[part 1 of 12: package /AUTOSAR_Dem/SwComponentTypes]
AUTOSAR XML (schema 4-2-2)
package /AUTOSAR_Dem/SwComponentTypes
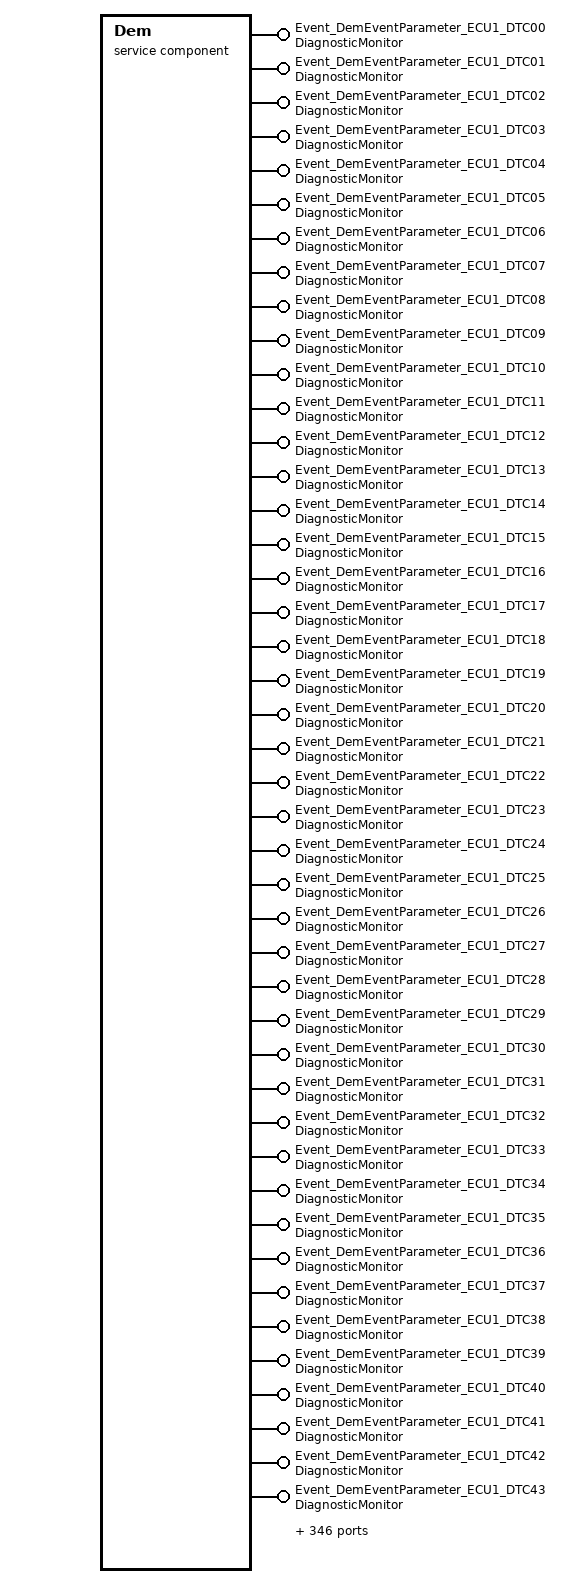
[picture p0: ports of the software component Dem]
  service sw component type Dem
    2013 x provide port:
      Event_DemEventParameter_ECU1_DTC00: provided-interface=DiagnosticMonitor
        provided-com-specs:
          operation=SetEventStatus, queue-length=1
          operation=SetEventStatusWithEnvdata, queue-length=1
          operation=ResetEventStatus, queue-length=1
          operation=PrestoreFreezeFrame, queue-length=1
          operation=ClearPrestoredFreezeFrame, queue-length=1
          operation=ResetEventDebounceStatus, queue-length=1
          operation=SetEventDisabled, queue-length=1
      Event_DemEventParameter_ECU1_DTC01: provided-interface=DiagnosticMonitor
        provided-com-specs:
          operation=SetEventStatus, queue-length=1
          operation=SetEventStatusWithEnvdata, queue-length=1
          operation=ResetEventStatus, queue-length=1
          operation=PrestoreFreezeFrame, queue-length=1
          operation=ClearPrestoredFreezeFrame, queue-length=1
          operation=ResetEventDebounceStatus, queue-length=1
          operation=SetEventDisabled, queue-length=1
      Event_DemEventParameter_ECU1_DTC02: provided-interface=DiagnosticMonitor
        provided-com-specs:
          operation=SetEventStatus, queue-length=1
          operation=SetEventStatusWithEnvdata, queue-length=1
          operation=ResetEventStatus, queue-length=1
          operation=PrestoreFreezeFrame, queue-length=1
          operation=ClearPrestoredFreezeFrame, queue-length=1
          operation=ResetEventDebounceStatus, queue-length=1
          operation=SetEventDisabled, queue-length=1
      Event_DemEventParameter_ECU1_DTC03: provided-interface=DiagnosticMonitor
        provided-com-specs:
          operation=SetEventStatus, queue-length=1
          operation=SetEventStatusWithEnvdata, queue-length=1
          operation=ResetEventStatus, queue-length=1
          operation=PrestoreFreezeFrame, queue-length=1
          operation=ClearPrestoredFreezeFrame, queue-length=1
          operation=ResetEventDebounceStatus, queue-length=1
          operation=SetEventDisabled, queue-length=1
      Event_DemEventParameter_ECU1_DTC04: provided-interface=DiagnosticMonitor
        provided-com-specs:
          operation=SetEventStatus, queue-length=1
          operation=SetEventStatusWithEnvdata, queue-length=1
          operation=ResetEventStatus, queue-length=1
          operation=PrestoreFreezeFrame, queue-length=1
          operation=ClearPrestoredFreezeFrame, queue-length=1
          operation=ResetEventDebounceStatus, queue-length=1
          operation=SetEventDisabled, queue-length=1
      Event_DemEventParameter_ECU1_DTC05: provided-interface=DiagnosticMonitor
        provided-com-specs:
          operation=SetEventStatus, queue-length=1
          operation=SetEventStatusWithEnvdata, queue-length=1
          operation=ResetEventStatus, queue-length=1
          operation=PrestoreFreezeFrame, queue-length=1
          operation=ClearPrestoredFreezeFrame, queue-length=1
          operation=ResetEventDebounceStatus, queue-length=1
          operation=SetEventDisabled, queue-length=1
      Event_DemEventParameter_ECU1_DTC06: provided-interface=DiagnosticMonitor
        provided-com-specs:
          operation=SetEventStatus, queue-length=1
          operation=SetEventStatusWithEnvdata, queue-length=1
          operation=ResetEventStatus, queue-length=1
          operation=PrestoreFreezeFrame, queue-length=1
          operation=ClearPrestoredFreezeFrame, queue-length=1
          operation=ResetEventDebounceStatus, queue-length=1
          operation=SetEventDisabled, queue-length=1
      Event_DemEventParameter_ECU1_DTC07: provided-interface=DiagnosticMonitor
        provided-com-specs:
          operation=SetEventStatus, queue-length=1
          operation=SetEventStatusWithEnvdata, queue-length=1
          operation=ResetEventStatus, queue-length=1
          operation=PrestoreFreezeFrame, queue-length=1
          operation=ClearPrestoredFreezeFrame, queue-length=1
          operation=ResetEventDebounceStatus, queue-length=1
          operation=SetEventDisabled, queue-length=1
      Event_DemEventParameter_ECU1_DTC08: provided-interface=DiagnosticMonitor
        provided-com-specs:
          operation=SetEventStatus, queue-length=1
          operation=SetEventStatusWithEnvdata, queue-length=1
          operation=ResetEventStatus, queue-length=1
          operation=PrestoreFreezeFrame, queue-length=1
          operation=ClearPrestoredFreezeFrame, queue-length=1
          operation=ResetEventDebounceStatus, queue-length=1
          operation=SetEventDisabled, queue-length=1
      Event_DemEventParameter_ECU1_DTC09: provided-interface=DiagnosticMonitor
        provided-com-specs:
          operation=SetEventStatus, queue-length=1
          operation=SetEventStatusWithEnvdata, queue-length=1
          operation=ResetEventStatus, queue-length=1
          operation=PrestoreFreezeFrame, queue-length=1
          operation=ClearPrestoredFreezeFrame, queue-length=1
          operation=ResetEventDebounceStatus, queue-length=1
          operation=SetEventDisabled, queue-length=1
      Event_DemEventParameter_ECU1_DTC10: provided-interface=DiagnosticMonitor
        provided-com-specs:
          operation=SetEventStatus, queue-length=1
          operation=SetEventStatusWithEnvdata, queue-length=1
          operation=ResetEventStatus, queue-length=1
          operation=PrestoreFreezeFrame, queue-length=1
          operation=ClearPrestoredFreezeFrame, queue-length=1
          operation=ResetEventDebounceStatus, queue-length=1
          operation=SetEventDisabled, queue-length=1
      Event_DemEventParameter_ECU1_DTC11: provided-interface=DiagnosticMonitor
        provided-com-specs:
          operation=SetEventStatus, queue-length=1
          operation=SetEventStatusWithEnvdata, queue-length=1
          operation=ResetEventStatus, queue-length=1
          operation=PrestoreFreezeFrame, queue-length=1
          operation=ClearPrestoredFreezeFrame, queue-length=1
          operation=ResetEventDebounceStatus, queue-length=1
          operation=SetEventDisabled, queue-length=1
      Event_DemEventParameter_ECU1_DTC12: provided-interface=DiagnosticMonitor
        provided-com-specs:
          operation=SetEventStatus, queue-length=1
          operation=SetEventStatusWithEnvdata, queue-length=1
          operation=ResetEventStatus, queue-length=1
          operation=PrestoreFreezeFrame, queue-length=1
          operation=ClearPrestoredFreezeFrame, queue-length=1
          operation=ResetEventDebounceStatus, queue-length=1
          operation=SetEventDisabled, queue-length=1
      Event_DemEventParameter_ECU1_DTC13: provided-interface=DiagnosticMonitor
        provided-com-specs:
          operation=SetEventStatus, queue-length=1
          operation=SetEventStatusWithEnvdata, queue-length=1
          operation=ResetEventStatus, queue-length=1
          operation=PrestoreFreezeFrame, queue-length=1
          operation=ClearPrestoredFreezeFrame, queue-length=1
          operation=ResetEventDebounceStatus, queue-length=1
          operation=SetEventDisabled, queue-length=1
      Event_DemEventParameter_ECU1_DTC14: provided-interface=DiagnosticMonitor
        provided-com-specs:
          operation=SetEventStatus, queue-length=1
          operation=SetEventStatusWithEnvdata, queue-length=1
          operation=ResetEventStatus, queue-length=1
          operation=PrestoreFreezeFrame, queue-length=1
          operation=ClearPrestoredFreezeFrame, queue-length=1
          operation=ResetEventDebounceStatus, queue-length=1
          operation=SetEventDisabled, queue-length=1
      Event_DemEventParameter_ECU1_DTC15: provided-interface=DiagnosticMonitor
        provided-com-specs:
          operation=SetEventStatus, queue-length=1
          operation=SetEventStatusWithEnvdata, queue-length=1
          operation=ResetEventStatus, queue-length=1
          operation=PrestoreFreezeFrame, queue-length=1
          operation=ClearPrestoredFreezeFrame, queue-length=1
          operation=ResetEventDebounceStatus, queue-length=1
          operation=SetEventDisabled, queue-length=1
      Event_DemEventParameter_ECU1_DTC16: provided-interface=DiagnosticMonitor
        provided-com-specs:
          operation=SetEventStatus, queue-length=1
          operation=SetEventStatusWithEnvdata, queue-length=1
          operation=ResetEventStatus, queue-length=1
          operation=PrestoreFreezeFrame, queue-length=1
          operation=ClearPrestoredFreezeFrame, queue-length=1
          operation=ResetEventDebounceStatus, queue-length=1
          operation=SetEventDisabled, queue-length=1
      Event_DemEventParameter_ECU1_DTC17: provided-interface=DiagnosticMonitor
        provided-com-specs:
          operation=SetEventStatus, queue-length=1
          operation=SetEventStatusWithEnvdata, queue-length=1
          operation=ResetEventStatus, queue-length=1
          operation=PrestoreFreezeFrame, queue-length=1
          operation=ClearPrestoredFreezeFrame, queue-length=1
          operation=ResetEventDebounceStatus, queue-length=1
          operation=SetEventDisabled, queue-length=1
      Event_DemEventParameter_ECU1_DTC18: provided-interface=DiagnosticMonitor
        provided-com-specs:
          operation=SetEventStatus, queue-length=1
          operation=SetEventStatusWithEnvdata, queue-length=1
          operation=ResetEventStatus, queue-length=1
          operation=PrestoreFreezeFrame, queue-length=1
          operation=ClearPrestoredFreezeFrame, queue-length=1
          operation=ResetEventDebounceStatus, queue-length=1
          operation=SetEventDisabled, queue-length=1
      Event_DemEventParameter_ECU1_DTC19: provided-interface=DiagnosticMonitor
        provided-com-specs:
          operation=SetEventStatus, queue-length=1
          operation=SetEventStatusWithEnvdata, queue-length=1
          operation=ResetEventStatus, queue-length=1
          operation=PrestoreFreezeFrame, queue-length=1
          operation=ClearPrestoredFreezeFrame, queue-length=1
          operation=ResetEventDebounceStatus, queue-length=1
          operation=SetEventDisabled, queue-length=1
      Event_DemEventParameter_ECU1_DTC20: provided-interface=DiagnosticMonitor
        provided-com-specs:
          operation=SetEventStatus, queue-length=1
          operation=SetEventStatusWithEnvdata, queue-length=1
          operation=ResetEventStatus, queue-length=1
          operation=PrestoreFreezeFrame, queue-length=1
          operation=ClearPrestoredFreezeFrame, queue-length=1
          operation=ResetEventDebounceStatus, queue-length=1
          operation=SetEventDisabled, queue-length=1
      Event_DemEventParameter_ECU1_DTC21: provided-interface=DiagnosticMonitor
        provided-com-specs:
          operation=SetEventStatus, queue-length=1
          operation=SetEventStatusWithEnvdata, queue-length=1
          operation=ResetEventStatus, queue-length=1
          operation=PrestoreFreezeFrame, queue-length=1
          operation=ClearPrestoredFreezeFrame, queue-length=1
          operation=ResetEventDebounceStatus, queue-length=1
          operation=SetEventDisabled, queue-length=1
      Event_DemEventParameter_ECU1_DTC22: provided-interface=DiagnosticMonitor
        provided-com-specs:
          operation=SetEventStatus, queue-length=1
          operation=SetEventStatusWithEnvdata, queue-length=1
          operation=ResetEventStatus, queue-length=1
          operation=PrestoreFreezeFrame, queue-length=1
          operation=ClearPrestoredFreezeFrame, queue-length=1
          operation=ResetEventDebounceStatus, queue-length=1
          operation=SetEventDisabled, queue-length=1
      Event_DemEventParameter_ECU1_DTC23: provided-interface=DiagnosticMonitor
        provided-com-specs:
          operation=SetEventStatus, queue-length=1
          operation=SetEventStatusWithEnvdata, queue-length=1
          operation=ResetEventStatus, queue-length=1
          operation=PrestoreFreezeFrame, queue-length=1
          operation=ClearPrestoredFreezeFrame, queue-length=1
          operation=ResetEventDebounceStatus, queue-length=1
          operation=SetEventDisabled, queue-length=1
      Event_DemEventParameter_ECU1_DTC24: provided-interface=DiagnosticMonitor
        provided-com-specs:
          operation=SetEventStatus, queue-length=1
          operation=SetEventStatusWithEnvdata, queue-length=1
          operation=ResetEventStatus, queue-length=1
          operation=PrestoreFreezeFrame, queue-length=1
          operation=ClearPrestoredFreezeFrame, queue-length=1
          operation=ResetEventDebounceStatus, queue-length=1
          operation=SetEventDisabled, queue-length=1
      Event_DemEventParameter_ECU1_DTC25: provided-interface=DiagnosticMonitor
        provided-com-specs:
          operation=SetEventStatus, queue-length=1
          operation=SetEventStatusWithEnvdata, queue-length=1
          operation=ResetEventStatus, queue-length=1
          operation=PrestoreFreezeFrame, queue-length=1
          operation=ClearPrestoredFreezeFrame, queue-length=1
          operation=ResetEventDebounceStatus, queue-length=1
          operation=SetEventDisabled, queue-length=1
      Event_DemEventParameter_ECU1_DTC26: provided-interface=DiagnosticMonitor
        provided-com-specs:
          operation=SetEventStatus, queue-length=1
          operation=SetEventStatusWithEnvdata, queue-length=1
          operation=ResetEventStatus, queue-length=1
          operation=PrestoreFreezeFrame, queue-length=1
          operation=ClearPrestoredFreezeFrame, queue-length=1
          operation=ResetEventDebounceStatus, queue-length=1
          operation=SetEventDisabled, queue-length=1
      Event_DemEventParameter_ECU1_DTC27: provided-interface=DiagnosticMonitor
        provided-com-specs:
          operation=SetEventStatus, queue-length=1
          operation=SetEventStatusWithEnvdata, queue-length=1
          operation=ResetEventStatus, queue-length=1
          operation=PrestoreFreezeFrame, queue-length=1
          operation=ClearPrestoredFreezeFrame, queue-length=1
          operation=ResetEventDebounceStatus, queue-length=1
          operation=SetEventDisabled, queue-length=1
      Event_DemEventParameter_ECU1_DTC28: provided-interface=DiagnosticMonitor
        provided-com-specs:
          operation=SetEventStatus, queue-length=1
          operation=SetEventStatusWithEnvdata, queue-length=1
          operation=ResetEventStatus, queue-length=1
          operation=PrestoreFreezeFrame, queue-length=1
          operation=ClearPrestoredFreezeFrame, queue-length=1
          operation=ResetEventDebounceStatus, queue-length=1
          operation=SetEventDisabled, queue-length=1
      Event_DemEventParameter_ECU1_DTC29: provided-interface=DiagnosticMonitor
        provided-com-specs:
          operation=SetEventStatus, queue-length=1
          operation=SetEventStatusWithEnvdata, queue-length=1
          operation=ResetEventStatus, queue-length=1
          operation=PrestoreFreezeFrame, queue-length=1
          operation=ClearPrestoredFreezeFrame, queue-length=1
          operation=ResetEventDebounceStatus, queue-length=1
          operation=SetEventDisabled, queue-length=1
      Event_DemEventParameter_ECU1_DTC30: provided-interface=DiagnosticMonitor
        provided-com-specs:
          operation=SetEventStatus, queue-length=1
          operation=SetEventStatusWithEnvdata, queue-length=1
          operation=ResetEventStatus, queue-length=1
          operation=PrestoreFreezeFrame, queue-length=1
          operation=ClearPrestoredFreezeFrame, queue-length=1
          operation=ResetEventDebounceStatus, queue-length=1
          operation=SetEventDisabled, queue-length=1
      Event_DemEventParameter_ECU1_DTC31: provided-interface=DiagnosticMonitor
        provided-com-specs:
          operation=SetEventStatus, queue-length=1
          operation=SetEventStatusWithEnvdata, queue-length=1
          operation=ResetEventStatus, queue-length=1
          operation=PrestoreFreezeFrame, queue-length=1
          operation=ClearPrestoredFreezeFrame, queue-length=1
          operation=ResetEventDebounceStatus, queue-length=1
          operation=SetEventDisabled, queue-length=1
      Event_DemEventParameter_ECU1_DTC32: provided-interface=DiagnosticMonitor
        provided-com-specs:
          operation=SetEventStatus, queue-length=1
          operation=SetEventStatusWithEnvdata, queue-length=1
          operation=ResetEventStatus, queue-length=1
          operation=PrestoreFreezeFrame, queue-length=1
          operation=ClearPrestoredFreezeFrame, queue-length=1
          operation=ResetEventDebounceStatus, queue-length=1
          operation=SetEventDisabled, queue-length=1
      Event_DemEventParameter_ECU1_DTC33: provided-interface=DiagnosticMonitor
        provided-com-specs:
          operation=SetEventStatus, queue-length=1
          operation=SetEventStatusWithEnvdata, queue-length=1
          operation=ResetEventStatus, queue-length=1
          operation=PrestoreFreezeFrame, queue-length=1
          operation=ClearPrestoredFreezeFrame, queue-length=1
          operation=ResetEventDebounceStatus, queue-length=1
          operation=SetEventDisabled, queue-length=1
      Event_DemEventParameter_ECU1_DTC34: provided-interface=DiagnosticMonitor
        provided-com-specs:
          operation=SetEventStatus, queue-length=1
          operation=SetEventStatusWithEnvdata, queue-length=1
          operation=ResetEventStatus, queue-length=1
          operation=PrestoreFreezeFrame, queue-length=1
          operation=ClearPrestoredFreezeFrame, queue-length=1
          operation=ResetEventDebounceStatus, queue-length=1
          operation=SetEventDisabled, queue-length=1
      Event_DemEventParameter_ECU1_DTC35: provided-interface=DiagnosticMonitor
        provided-com-specs:
          operation=SetEventStatus, queue-length=1
          operation=SetEventStatusWithEnvdata, queue-length=1
          operation=ResetEventStatus, queue-length=1
          operation=PrestoreFreezeFrame, queue-length=1
          operation=ClearPrestoredFreezeFrame, queue-length=1
          operation=ResetEventDebounceStatus, queue-length=1
          operation=SetEventDisabled, queue-length=1
      Event_DemEventParameter_ECU1_DTC36: provided-interface=DiagnosticMonitor
        provided-com-specs:
          operation=SetEventStatus, queue-length=1
          operation=SetEventStatusWithEnvdata, queue-length=1
          operation=ResetEventStatus, queue-length=1
          operation=PrestoreFreezeFrame, queue-length=1
          operation=ClearPrestoredFreezeFrame, queue-length=1
          operation=ResetEventDebounceStatus, queue-length=1
          operation=SetEventDisabled, queue-length=1
      Event_DemEventParameter_ECU1_DTC37: provided-interface=DiagnosticMonitor
        provided-com-specs:
          operation=SetEventStatus, queue-length=1
          operation=SetEventStatusWithEnvdata, queue-length=1
          operation=ResetEventStatus, queue-length=1
          operation=PrestoreFreezeFrame, queue-length=1
          operation=ClearPrestoredFreezeFrame, queue-length=1
          operation=ResetEventDebounceStatus, queue-length=1
          operation=SetEventDisabled, queue-length=1
      Event_DemEventParameter_ECU1_DTC38: provided-interface=DiagnosticMonitor
        provided-com-specs:
          operation=SetEventStatus, queue-length=1
          operation=SetEventStatusWithEnvdata, queue-length=1
          operation=ResetEventStatus, queue-length=1
          operation=PrestoreFreezeFrame, queue-length=1
          operation=ClearPrestoredFreezeFrame, queue-length=1
          operation=ResetEventDebounceStatus, queue-length=1
          operation=SetEventDisabled, queue-length=1
      Event_DemEventParameter_ECU1_DTC39: provided-interface=DiagnosticMonitor
        provided-com-specs:
          operation=SetEventStatus, queue-length=1
          operation=SetEventStatusWithEnvdata, queue-length=1
          operation=ResetEventStatus, queue-length=1
          operation=PrestoreFreezeFrame, queue-length=1
          operation=ClearPrestoredFreezeFrame, queue-length=1
          operation=ResetEventDebounceStatus, queue-length=1
          operation=SetEventDisabled, queue-length=1
      Event_DemEventParameter_ECU1_DTC40: provided-interface=DiagnosticMonitor
        provided-com-specs:
          operation=SetEventStatus, queue-length=1
          operation=SetEventStatusWithEnvdata, queue-length=1
          operation=ResetEventStatus, queue-length=1
          operation=PrestoreFreezeFrame, queue-length=1
          operation=ClearPrestoredFreezeFrame, queue-length=1
          operation=ResetEventDebounceStatus, queue-length=1
          operation=SetEventDisabled, queue-length=1
      Event_DemEventParameter_ECU1_DTC41: provided-interface=DiagnosticMonitor
        provided-com-specs:
          operation=SetEventStatus, queue-length=1
          operation=SetEventStatusWithEnvdata, queue-length=1
          operation=ResetEventStatus, queue-length=1
          operation=PrestoreFreezeFrame, queue-length=1
          operation=ClearPrestoredFreezeFrame, queue-length=1
          operation=ResetEventDebounceStatus, queue-length=1
          operation=SetEventDisabled, queue-length=1
      Event_DemEventParameter_ECU1_DTC42: provided-interface=DiagnosticMonitor
        provided-com-specs:
          operation=SetEventStatus, queue-length=1
          operation=SetEventStatusWithEnvdata, queue-length=1
          operation=ResetEventStatus, queue-length=1
          operation=PrestoreFreezeFrame, queue-length=1
          operation=ClearPrestoredFreezeFrame, queue-length=1
          operation=ResetEventDebounceStatus, queue-length=1
          operation=SetEventDisabled, queue-length=1
      Event_DemEventParameter_ECU1_DTC43: provided-interface=DiagnosticMonitor
        provided-com-specs:
          operation=SetEventStatus, queue-length=1
          operation=SetEventStatusWithEnvdata, queue-length=1
          operation=ResetEventStatus, queue-length=1
          operation=PrestoreFreezeFrame, queue-length=1
          operation=ClearPrestoredFreezeFrame, queue-length=1
          operation=ResetEventDebounceStatus, queue-length=1
          operation=SetEventDisabled, queue-length=1
      Event_DemEventParameter_ECU1_DTC44: provided-interface=DiagnosticMonitor
        provided-com-specs:
          operation=SetEventStatus, queue-length=1
          operation=SetEventStatusWithEnvdata, queue-length=1
          operation=ResetEventStatus, queue-length=1
          operation=PrestoreFreezeFrame, queue-length=1
          operation=ClearPrestoredFreezeFrame, queue-length=1
          operation=ResetEventDebounceStatus, queue-length=1
          operation=SetEventDisabled, queue-length=1
      Event_DemEventParameter_ECU1_DTC45: provided-interface=DiagnosticMonitor
        provided-com-specs:
          operation=SetEventStatus, queue-length=1
          operation=SetEventStatusWithEnvdata, queue-length=1
          operation=ResetEventStatus, queue-length=1
          operation=PrestoreFreezeFrame, queue-length=1
          operation=ClearPrestoredFreezeFrame, queue-length=1
          operation=ResetEventDebounceStatus, queue-length=1
          operation=SetEventDisabled, queue-length=1
      Event_DemEventParameter_ECU1_DTC46: provided-interface=DiagnosticMonitor
        provided-com-specs:
          operation=SetEventStatus, queue-length=1
          operation=SetEventStatusWithEnvdata, queue-length=1
          operation=ResetEventStatus, queue-length=1
          operation=PrestoreFreezeFrame, queue-length=1
          operation=ClearPrestoredFreezeFrame, queue-length=1
          operation=ResetEventDebounceStatus, queue-length=1
          operation=SetEventDisabled, queue-length=1
      Event_DemEventParameter_ECU1_DTC47: provided-interface=DiagnosticMonitor
        provided-com-specs:
          operation=SetEventStatus, queue-length=1
          operation=SetEventStatusWithEnvdata, queue-length=1
          operation=ResetEventStatus, queue-length=1
          operation=PrestoreFreezeFrame, queue-length=1
          operation=ClearPrestoredFreezeFrame, queue-length=1
          operation=ResetEventDebounceStatus, queue-length=1
          operation=SetEventDisabled, queue-length=1
      Event_DemEventParameter_ECU1_DTC48: provided-interface=DiagnosticMonitor
        provided-com-specs:
          operation=SetEventStatus, queue-length=1
          operation=SetEventStatusWithEnvdata, queue-length=1
          operation=ResetEventStatus, queue-length=1
          operation=PrestoreFreezeFrame, queue-length=1
          operation=ClearPrestoredFreezeFrame, queue-length=1
          operation=ResetEventDebounceStatus, queue-length=1
          operation=SetEventDisabled, queue-length=1
      Event_DemEventParameter_ECU1_DTC49: provided-interface=DiagnosticMonitor
        provided-com-specs:
          operation=SetEventStatus, queue-length=1
          operation=SetEventStatusWithEnvdata, queue-length=1
          operation=ResetEventStatus, queue-length=1
          operation=PrestoreFreezeFrame, queue-length=1
          operation=ClearPrestoredFreezeFrame, queue-length=1
          operation=ResetEventDebounceStatus, queue-length=1
          operation=SetEventDisabled, queue-length=1
      Event_DemEventParameter_ECU1_DTC50: provided-interface=DiagnosticMonitor
        provided-com-specs:
          operation=SetEventStatus, queue-length=1
          operation=SetEventStatusWithEnvdata, queue-length=1
          operation=ResetEventStatus, queue-length=1
          operation=PrestoreFreezeFrame, queue-length=1
          operation=ClearPrestoredFreezeFrame, queue-length=1
          operation=ResetEventDebounceStatus, queue-length=1
          operation=SetEventDisabled, queue-length=1
      Event_DemEventParameter_ECU1_DTC51: provided-interface=DiagnosticMonitor
        provided-com-specs:
          operation=SetEventStatus, queue-length=1
          operation=SetEventStatusWithEnvdata, queue-length=1
          operation=ResetEventStatus, queue-length=1
          operation=PrestoreFreezeFrame, queue-length=1
          operation=ClearPrestoredFreezeFrame, queue-length=1
          operation=ResetEventDebounceStatus, queue-length=1
          operation=SetEventDisabled, queue-length=1
      Event_DemEventParameter_ECU1_DTC52: provided-interface=DiagnosticMonitor
        provided-com-specs:
          operation=SetEventStatus, queue-length=1
          operation=SetEventStatusWithEnvdata, queue-length=1
          operation=ResetEventStatus, queue-length=1
          operation=PrestoreFreezeFrame, queue-length=1
          operation=ClearPrestoredFreezeFrame, queue-length=1
          operation=ResetEventDebounceStatus, queue-length=1
          operation=SetEventDisabled, queue-length=1
      Event_DemEventParameter_ECU1_DTC53: provided-interface=DiagnosticMonitor
        provided-com-specs:
          operation=SetEventStatus, queue-length=1
          operation=SetEventStatusWithEnvdata, queue-length=1
          operation=ResetEventStatus, queue-length=1
          operation=PrestoreFreezeFrame, queue-length=1
          operation=ClearPrestoredFreezeFrame, queue-length=1
          operation=ResetEventDebounceStatus, queue-length=1
          operation=SetEventDisabled, queue-length=1
      Event_DemEventParameter_ECU1_DTC54: provided-interface=DiagnosticMonitor
        provided-com-specs:
          operation=SetEventStatus, queue-length=1
          operation=SetEventStatusWithEnvdata, queue-length=1
          operation=ResetEventStatus, queue-length=1
          operation=PrestoreFreezeFrame, queue-length=1
          operation=ClearPrestoredFreezeFrame, queue-length=1
          operation=ResetEventDebounceStatus, queue-length=1
          operation=SetEventDisabled, queue-length=1
      Event_DemEventParameter_ECU1_DTC55: provided-interface=DiagnosticMonitor
        provided-com-specs:
          operation=SetEventStatus, queue-length=1
          operation=SetEventStatusWithEnvdata, queue-length=1
          operation=ResetEventStatus, queue-length=1
          operation=PrestoreFreezeFrame, queue-length=1
          operation=ClearPrestoredFreezeFrame, queue-length=1
          operation=ResetEventDebounceStatus, queue-length=1
          operation=SetEventDisabled, queue-length=1
      Event_DemEventParameter_ECU1_DTC56: provided-interface=DiagnosticMonitor
        provided-com-specs:
          operation=SetEventStatus, queue-length=1
          operation=SetEventStatusWithEnvdata, queue-length=1
          operation=ResetEventStatus, queue-length=1
          operation=PrestoreFreezeFrame, queue-length=1
          operation=ClearPrestoredFreezeFrame, queue-length=1
          operation=ResetEventDebounceStatus, queue-length=1
          operation=SetEventDisabled, queue-length=1
      Event_DemEventParameter_ECU1_DTC57: provided-interface=DiagnosticMonitor
        provided-com-specs:
          operation=SetEventStatus, queue-length=1
          operation=SetEventStatusWithEnvdata, queue-length=1
          operation=ResetEventStatus, queue-length=1
          operation=PrestoreFreezeFrame, queue-length=1
          operation=ClearPrestoredFreezeFrame, queue-length=1
          operation=ResetEventDebounceStatus, queue-length=1
          operation=SetEventDisabled, queue-length=1
      Event_DemEventParameter_ECU1_DTC58: provided-interface=DiagnosticMonitor
        provided-com-specs:
          operation=SetEventStatus, queue-length=1
          operation=SetEventStatusWithEnvdata, queue-length=1
          operation=ResetEventStatus, queue-length=1
          operation=PrestoreFreezeFrame, queue-length=1
          operation=ClearPrestoredFreezeFrame, queue-length=1
          operation=ResetEventDebounceStatus, queue-length=1
          operation=SetEventDisabled, queue-length=1
      Event_DemEventParameter_ECU1_DTC59: provided-interface=DiagnosticMonitor
        provided-com-specs:
          operation=SetEventStatus, queue-length=1
          operation=SetEventStatusWithEnvdata, queue-length=1
          operation=ResetEventStatus, queue-length=1
          operation=PrestoreFreezeFrame, queue-length=1
          operation=ClearPrestoredFreezeFrame, queue-length=1
          operation=ResetEventDebounceStatus, queue-length=1
          operation=SetEventDisabled, queue-length=1
      Event_DemEventParameter_ECU1_DTC60: provided-interface=DiagnosticMonitor
        provided-com-specs:
          operation=SetEventStatus, queue-length=1
          operation=SetEventStatusWithEnvdata, queue-length=1
          operation=ResetEventStatus, queue-length=1
          operation=PrestoreFreezeFrame, queue-length=1
          operation=ClearPrestoredFreezeFrame, queue-length=1
          operation=ResetEventDebounceStatus, queue-length=1
          operation=SetEventDisabled, queue-length=1
      Event_DemEventParameter_ECU1_DTC61: provided-interface=DiagnosticMonitor
        provided-com-specs:
          operation=SetEventStatus, queue-length=1
          operation=SetEventStatusWithEnvdata, queue-length=1
          operation=ResetEventStatus, queue-length=1
          operation=PrestoreFreezeFrame, queue-length=1
          operation=ClearPrestoredFreezeFrame, queue-length=1
          operation=ResetEventDebounceStatus, queue-length=1
          operation=SetEventDisabled, queue-length=1
      Event_DemEventParameter_ECU1_DTC62: provided-interface=DiagnosticMonitor
        provided-com-specs:
          operation=SetEventStatus, queue-length=1
          operation=SetEventStatusWithEnvdata, queue-length=1
          operation=ResetEventStatus, queue-length=1
          operation=PrestoreFreezeFrame, queue-length=1
          operation=ClearPrestoredFreezeFrame, queue-length=1
          operation=ResetEventDebounceStatus, queue-length=1
          operation=SetEventDisabled, queue-length=1
      Event_DemEventParameter_ECU1_DTC63: provided-interface=DiagnosticMonitor
        provided-com-specs:
          operation=SetEventStatus, queue-length=1
          operation=SetEventStatusWithEnvdata, queue-length=1
          operation=ResetEventStatus, queue-length=1
          operation=PrestoreFreezeFrame, queue-length=1
          operation=ClearPrestoredFreezeFrame, queue-length=1
          operation=ResetEventDebounceStatus, queue-length=1
          operation=SetEventDisabled, queue-length=1
      Event_DemEventParameter_ECU1_DTC64: provided-interface=DiagnosticMonitor
        provided-com-specs:
          operation=SetEventStatus, queue-length=1
          operation=SetEventStatusWithEnvdata, queue-length=1
          operation=ResetEventStatus, queue-length=1
          operation=PrestoreFreezeFrame, queue-length=1
          operation=ClearPrestoredFreezeFrame, queue-length=1
          operation=ResetEventDebounceStatus, queue-length=1
          operation=SetEventDisabled, queue-length=1
      Event_DemEventParameter_ECU1_DTC65: provided-interface=DiagnosticMonitor
        provided-com-specs:
          operation=SetEventStatus, queue-length=1
          operation=SetEventStatusWithEnvdata, queue-length=1
          operation=ResetEventStatus, queue-length=1
          operation=PrestoreFreezeFrame, queue-length=1
          operation=ClearPrestoredFreezeFrame, queue-length=1
          operation=ResetEventDebounceStatus, queue-length=1
          operation=SetEventDisabled, queue-length=1
      Event_DemEventParameter_ECU1_DTC66: provided-interface=DiagnosticMonitor
        provided-com-specs:
          operation=SetEventStatus, queue-length=1
          operation=SetEventStatusWithEnvdata, queue-length=1
          operation=ResetEventStatus, queue-length=1
          operation=PrestoreFreezeFrame, queue-length=1
          operation=ClearPrestoredFreezeFrame, queue-length=1
          operation=ResetEventDebounceStatus, queue-length=1
          operation=SetEventDisabled, queue-length=1
      Event_DemEventParameter_ECU1_DTC67: provided-interface=DiagnosticMonitor
        provided-com-specs:
          operation=SetEventStatus, queue-length=1
          operation=SetEventStatusWithEnvdata, queue-length=1
          operation=ResetEventStatus, queue-length=1
          operation=PrestoreFreezeFrame, queue-length=1
          operation=ClearPrestoredFreezeFrame, queue-length=1
          operation=ResetEventDebounceStatus, queue-length=1
          operation=SetEventDisabled, queue-length=1
      Event_DemEventParameter_ECU1_DTC68: provided-interface=DiagnosticMonitor
        provided-com-specs:
          operation=SetEventStatus, queue-length=1
          operation=SetEventStatusWithEnvdata, queue-length=1
          operation=ResetEventStatus, queue-length=1
          operation=PrestoreFreezeFrame, queue-length=1
          operation=ClearPrestoredFreezeFrame, queue-length=1
          operation=ResetEventDebounceStatus, queue-length=1
          operation=SetEventDisabled, queue-length=1
      Event_DemEventParameter_ECU1_DTC69: provided-interface=DiagnosticMonitor
        provided-com-specs:
          operation=SetEventStatus, queue-length=1
          operation=SetEventStatusWithEnvdata, queue-length=1
          operation=ResetEventStatus, queue-length=1
          operation=PrestoreFreezeFrame, queue-length=1
          operation=ClearPrestoredFreezeFrame, queue-length=1
          operation=ResetEventDebounceStatus, queue-length=1
          operation=SetEventDisabled, queue-length=1
      Event_DemEventParameter_ECU1_DTC70: provided-interface=DiagnosticMonitor
        provided-com-specs:
          operation=SetEventStatus, queue-length=1
          operation=SetEventStatusWithEnvdata, queue-length=1
          operation=ResetEventStatus, queue-length=1
          operation=PrestoreFreezeFrame, queue-length=1
          operation=ClearPrestoredFreezeFrame, queue-length=1
          operation=ResetEventDebounceStatus, queue-length=1
          operation=SetEventDisabled, queue-length=1
      Event_DemEventParameter_ECU1_DTC71: provided-interface=DiagnosticMonitor
        provided-com-specs:
          operation=SetEventStatus, queue-length=1
          operation=SetEventStatusWithEnvdata, queue-length=1
          operation=ResetEventStatus, queue-length=1
          operation=PrestoreFreezeFrame, queue-length=1
          operation=ClearPrestoredFreezeFrame, queue-length=1
          operation=ResetEventDebounceStatus, queue-length=1
          operation=SetEventDisabled, queue-length=1
      Event_DemEventParameter_ECU1_DTC72: provided-interface=DiagnosticMonitor
        provided-com-specs:
          operation=SetEventStatus, queue-length=1
          operation=SetEventStatusWithEnvdata, queue-length=1
          operation=ResetEventStatus, queue-length=1
          operation=PrestoreFreezeFrame, queue-length=1
          operation=ClearPrestoredFreezeFrame, queue-length=1
          operation=ResetEventDebounceStatus, queue-length=1
          operation=SetEventDisabled, queue-length=1
      Event_DemEventParameter_ECU1_DTC73: provided-interface=DiagnosticMonitor
        provided-com-specs:
          operation=SetEventStatus, queue-length=1
          operation=SetEventStatusWithEnvdata, queue-length=1
          operation=ResetEventStatus, queue-length=1
          operation=PrestoreFreezeFrame, queue-length=1
          operation=ClearPrestoredFreezeFrame, queue-length=1
          operation=ResetEventDebounceStatus, queue-length=1
          operation=SetEventDisabled, queue-length=1
      Event_DemEventParameter_ECU1_DTC74: provided-interface=DiagnosticMonitor
        provided-com-specs:
          operation=SetEventStatus, queue-length=1
          operation=SetEventStatusWithEnvdata, queue-length=1
          operation=ResetEventStatus, queue-length=1
          operation=PrestoreFreezeFrame, queue-length=1
          operation=ClearPrestoredFreezeFrame, queue-length=1
          operation=ResetEventDebounceStatus, queue-length=1
          operation=SetEventDisabled, queue-length=1
      Event_DemEventParameter_ECU1_DTC75: provided-interface=DiagnosticMonitor
        provided-com-specs:
          operation=SetEventStatus, queue-length=1
          operation=SetEventStatusWithEnvdata, queue-length=1
          operation=ResetEventStatus, queue-length=1
          operation=PrestoreFreezeFrame, queue-length=1
          operation=ClearPrestoredFreezeFrame, queue-length=1
          operation=ResetEventDebounceStatus, queue-length=1
          operation=SetEventDisabled, queue-length=1
      Event_DemEventParameter_ECU1_DTC76: provided-interface=DiagnosticMonitor
        provided-com-specs:
          operation=SetEventStatus, queue-length=1
          operation=SetEventStatusWithEnvdata, queue-length=1
          operation=ResetEventStatus, queue-length=1
          operation=PrestoreFreezeFrame, queue-length=1
          operation=ClearPrestoredFreezeFrame, queue-length=1
          operation=ResetEventDebounceStatus, queue-length=1
          operation=SetEventDisabled, queue-length=1
      Event_DemEventParameter_ECU1_DTC77: provided-interface=DiagnosticMonitor
        provided-com-specs:
          operation=SetEventStatus, queue-length=1
          operation=SetEventStatusWithEnvdata, queue-length=1
          operation=ResetEventStatus, queue-length=1
          operation=PrestoreFreezeFrame, queue-length=1
          operation=ClearPrestoredFreezeFrame, queue-length=1
          operation=ResetEventDebounceStatus, queue-length=1
          operation=SetEventDisabled, queue-length=1
      Event_DemEventParameter_ECU1_DTC78: provided-interface=DiagnosticMonitor
        provided-com-specs:
          operation=SetEventStatus, queue-length=1
          operation=SetEventStatusWithEnvdata, queue-length=1
          operation=ResetEventStatus, queue-length=1
          operation=PrestoreFreezeFrame, queue-length=1
          operation=ClearPrestoredFreezeFrame, queue-length=1
          operation=ResetEventDebounceStatus, queue-length=1
          operation=SetEventDisabled, queue-length=1
      Event_DemEventParameter_ECU1_DTC79: provided-interface=DiagnosticMonitor
        provided-com-specs:
          operation=SetEventStatus, queue-length=1
          operation=SetEventStatusWithEnvdata, queue-length=1
          operation=ResetEventStatus, queue-length=1
          operation=PrestoreFreezeFrame, queue-length=1
          operation=ClearPrestoredFreezeFrame, queue-length=1
          operation=ResetEventDebounceStatus, queue-length=1
          operation=SetEventDisabled, queue-length=1
      Event_DemEventParameter_ECU1_DTC80: provided-interface=DiagnosticMonitor
        provided-com-specs:
          operation=SetEventStatus, queue-length=1
          operation=SetEventStatusWithEnvdata, queue-length=1
          operation=ResetEventStatus, queue-length=1
          operation=PrestoreFreezeFrame, queue-length=1
          operation=ClearPrestoredFreezeFrame, queue-length=1
          operation=ResetEventDebounceStatus, queue-length=1
          operation=SetEventDisabled, queue-length=1
      Event_DemEventParameter_ECU1_DTC81: provided-interface=DiagnosticMonitor
        provided-com-specs:
          operation=SetEventStatus, queue-length=1
          operation=SetEventStatusWithEnvdata, queue-length=1
          operation=ResetEventStatus, queue-length=1
          operation=PrestoreFreezeFrame, queue-length=1
          operation=ClearPrestoredFreezeFrame, queue-length=1
          operation=ResetEventDebounceStatus, queue-length=1
          operation=SetEventDisabled, queue-length=1
      Event_DemEventParameter_ECU1_DTC82: provided-interface=DiagnosticMonitor
        provided-com-specs:
          operation=SetEventStatus, queue-length=1
          operation=SetEventStatusWithEnvdata, queue-length=1
          operation=ResetEventStatus, queue-length=1
          operation=PrestoreFreezeFrame, queue-length=1
          operation=ClearPrestoredFreezeFrame, queue-length=1
          operation=ResetEventDebounceStatus, queue-length=1
          operation=SetEventDisabled, queue-length=1
      Event_DemEventParameter_ECU1_DTC83: provided-interface=DiagnosticMonitor
        provided-com-specs:
          operation=SetEventStatus, queue-length=1
          operation=SetEventStatusWithEnvdata, queue-length=1
          operation=ResetEventStatus, queue-length=1
          operation=PrestoreFreezeFrame, queue-length=1
          operation=ClearPrestoredFreezeFrame, queue-length=1
          operation=ResetEventDebounceStatus, queue-length=1
          operation=SetEventDisabled, queue-length=1
      Event_DemEventParameter_ECU1_DTC84: provided-interface=DiagnosticMonitor
        provided-com-specs:
          operation=SetEventStatus, queue-length=1
          operation=SetEventStatusWithEnvdata, queue-length=1
          operation=ResetEventStatus, queue-length=1
          operation=PrestoreFreezeFrame, queue-length=1
          operation=ClearPrestoredFreezeFrame, queue-length=1
          operation=ResetEventDebounceStatus, queue-length=1
          operation=SetEventDisabled, queue-length=1
      Event_DemEventParameter_ECU1_DTC85: provided-interface=DiagnosticMonitor
        provided-com-specs:
          operation=SetEventStatus, queue-length=1
          operation=SetEventStatusWithEnvdata, queue-length=1
          operation=ResetEventStatus, queue-length=1
          operation=PrestoreFreezeFrame, queue-length=1
          operation=ClearPrestoredFreezeFrame, queue-length=1
          operation=ResetEventDebounceStatus, queue-length=1
          operation=SetEventDisabled, queue-length=1
      Event_DemEventParameter_ECU1_DTC86: provided-interface=DiagnosticMonitor
        provided-com-specs:
          operation=SetEventStatus, queue-length=1
          operation=SetEventStatusWithEnvdata, queue-length=1
          operation=ResetEventStatus, queue-length=1
          operation=PrestoreFreezeFrame, queue-length=1
          operation=ClearPrestoredFreezeFrame, queue-length=1
          operation=ResetEventDebounceStatus, queue-length=1
          operation=SetEventDisabled, queue-length=1
      Event_DemEventParameter_ECU1_DTC87: provided-interface=DiagnosticMonitor
        provided-com-specs:
          operation=SetEventStatus, queue-length=1
          operation=SetEventStatusWithEnvdata, queue-length=1
          operation=ResetEventStatus, queue-length=1
          operation=PrestoreFreezeFrame, queue-length=1
          operation=ClearPrestoredFreezeFrame, queue-length=1
          operation=ResetEventDebounceStatus, queue-length=1
          operation=SetEventDisabled, queue-length=1
      Event_DemEventParameter_ECU1_DTC88: provided-interface=DiagnosticMonitor
        provided-com-specs:
          operation=SetEventStatus, queue-length=1
          operation=SetEventStatusWithEnvdata, queue-length=1
          operation=ResetEventStatus, queue-length=1
          operation=PrestoreFreezeFrame, queue-length=1
          operation=ClearPrestoredFreezeFrame, queue-length=1
          operation=ResetEventDebounceStatus, queue-length=1
          operation=SetEventDisabled, queue-length=1
      Event_DemEventParameter_ECU1_DTC89: provided-interface=DiagnosticMonitor
        provided-com-specs:
          operation=SetEventStatus, queue-length=1
          operation=SetEventStatusWithEnvdata, queue-length=1
          operation=ResetEventStatus, queue-length=1
          operation=PrestoreFreezeFrame, queue-length=1
          operation=ClearPrestoredFreezeFrame, queue-length=1
          operation=ResetEventDebounceStatus, queue-length=1
          operation=SetEventDisabled, queue-length=1
      Event_DemEventParameter_ECU1_DTC90: provided-interface=DiagnosticMonitor
        provided-com-specs:
          operation=SetEventStatus, queue-length=1
          operation=SetEventStatusWithEnvdata, queue-length=1
          operation=ResetEventStatus, queue-length=1
          operation=PrestoreFreezeFrame, queue-length=1
          operation=ClearPrestoredFreezeFrame, queue-length=1
          operation=ResetEventDebounceStatus, queue-length=1
          operation=SetEventDisabled, queue-length=1
      Event_DemEventParameter_ECU1_DTC91: provided-interface=DiagnosticMonitor
        provided-com-specs:
          operation=SetEventStatus, queue-length=1
          operation=SetEventStatusWithEnvdata, queue-length=1
          operation=ResetEventStatus, queue-length=1
          operation=PrestoreFreezeFrame, queue-length=1
          operation=ClearPrestoredFreezeFrame, queue-length=1
          operation=ResetEventDebounceStatus, queue-length=1
          operation=SetEventDisabled, queue-length=1
      Event_DemEventParameter_ECU1_DTC92: provided-interface=DiagnosticMonitor
        provided-com-specs:
          operation=SetEventStatus, queue-length=1
          operation=SetEventStatusWithEnvdata, queue-length=1
          operation=ResetEventStatus, queue-length=1
          operation=PrestoreFreezeFrame, queue-length=1
          operation=ClearPrestoredFreezeFrame, queue-length=1
          operation=ResetEventDebounceStatus, queue-length=1
          operation=SetEventDisabled, queue-length=1
      Event_DemEventParameter_ECU1_DTC93: provided-interface=DiagnosticMonitor
        provided-com-specs:
          operation=SetEventStatus, queue-length=1
          operation=SetEventStatusWithEnvdata, queue-length=1
          operation=ResetEventStatus, queue-length=1
          operation=PrestoreFreezeFrame, queue-length=1
          operation=ClearPrestoredFreezeFrame, queue-length=1
          operation=ResetEventDebounceStatus, queue-length=1
          operation=SetEventDisabled, queue-length=1
      Event_DemEventParameter_ECU1_DTC94: provided-interface=DiagnosticMonitor
        provided-com-specs:
          operation=SetEventStatus, queue-length=1
          operation=SetEventStatusWithEnvdata, queue-length=1
          operation=ResetEventStatus, queue-length=1
          operation=PrestoreFreezeFrame, queue-length=1
          operation=ClearPrestoredFreezeFrame, queue-length=1
          operation=ResetEventDebounceStatus, queue-length=1
          operation=SetEventDisabled, queue-length=1
      Event_DemEventParameter_ECU1_DTC95: provided-interface=DiagnosticMonitor
        provided-com-specs:
          operation=SetEventStatus, queue-length=1
          operation=SetEventStatusWithEnvdata, queue-length=1
          operation=ResetEventStatus, queue-length=1
          operation=PrestoreFreezeFrame, queue-length=1
          operation=ClearPrestoredFreezeFrame, queue-length=1
          operation=ResetEventDebounceStatus, queue-length=1
          operation=SetEventDisabled, queue-length=1
      Event_DemEventParameter_ECU1_DTC96: provided-interface=DiagnosticMonitor
        provided-com-specs:
          operation=SetEventStatus, queue-length=1
          operation=SetEventStatusWithEnvdata, queue-length=1
          operation=ResetEventStatus, queue-length=1
          operation=PrestoreFreezeFrame, queue-length=1
          operation=ClearPrestoredFreezeFrame, queue-length=1
          operation=ResetEventDebounceStatus, queue-length=1
          operation=SetEventDisabled, queue-length=1
      Event_DemEventParameter_ECU1_DTC97: provided-interface=DiagnosticMonitor
        provided-com-specs:
          operation=SetEventStatus, queue-length=1
          operation=SetEventStatusWithEnvdata, queue-length=1
          operation=ResetEventStatus, queue-length=1
          operation=PrestoreFreezeFrame, queue-length=1
          operation=ClearPrestoredFreezeFrame, queue-length=1
          operation=ResetEventDebounceStatus, queue-length=1
          operation=SetEventDisabled, queue-length=1
      Event_DemEventParameter_ECU1_DTC98: provided-interface=DiagnosticMonitor
        provided-com-specs:
          operation=SetEventStatus, queue-length=1
          operation=SetEventStatusWithEnvdata, queue-length=1
          operation=ResetEventStatus, queue-length=1
          operation=PrestoreFreezeFrame, queue-length=1
          operation=ClearPrestoredFreezeFrame, queue-length=1
          operation=ResetEventDebounceStatus, queue-length=1
          operation=SetEventDisabled, queue-length=1
      Event_DemEventParameter_ECU1_DTC99: provided-interface=DiagnosticMonitor
        provided-com-specs:
          operation=SetEventStatus, queue-length=1
          operation=SetEventStatusWithEnvdata, queue-length=1
          operation=ResetEventStatus, queue-length=1
          operation=PrestoreFreezeFrame, queue-length=1
          operation=ClearPrestoredFreezeFrame, queue-length=1
          operation=ResetEventDebounceStatus, queue-length=1
          operation=SetEventDisabled, queue-length=1
      Event_DemEventParameter_ECU2_DTC00: provided-interface=DiagnosticMonitor
        provided-com-specs:
          operation=SetEventStatus, queue-length=1
          operation=SetEventStatusWithEnvdata, queue-length=1
          operation=ResetEventStatus, queue-length=1
          operation=PrestoreFreezeFrame, queue-length=1
          operation=ClearPrestoredFreezeFrame, queue-length=1
          operation=ResetEventDebounceStatus, queue-length=1
          operation=SetEventDisabled, queue-length=1
      Event_DemEventParameter_ECU2_DTC01: provided-interface=DiagnosticMonitor
        provided-com-specs:
          operation=SetEventStatus, queue-length=1
          operation=SetEventStatusWithEnvdata, queue-length=1
          operation=ResetEventStatus, queue-length=1
          operation=PrestoreFreezeFrame, queue-length=1
          operation=ClearPrestoredFreezeFrame, queue-length=1
          operation=ResetEventDebounceStatus, queue-length=1
          operation=SetEventDisabled, queue-length=1
      Event_DemEventParameter_ECU2_DTC02: provided-interface=DiagnosticMonitor
        provided-com-specs:
          operation=SetEventStatus, queue-length=1
          operation=SetEventStatusWithEnvdata, queue-length=1
          operation=ResetEventStatus, queue-length=1
          operation=PrestoreFreezeFrame, queue-length=1
          operation=ClearPrestoredFreezeFrame, queue-length=1
          operation=ResetEventDebounceStatus, queue-length=1
          operation=SetEventDisabled, queue-length=1
      Event_DemEventParameter_ECU2_DTC03: provided-interface=DiagnosticMonitor
        provided-com-specs:
          operation=SetEventStatus, queue-length=1
          operation=SetEventStatusWithEnvdata, queue-length=1
          operation=ResetEventStatus, queue-length=1
          operation=PrestoreFreezeFrame, queue-length=1
          operation=ClearPrestoredFreezeFrame, queue-length=1
          operation=ResetEventDebounceStatus, queue-length=1
          operation=SetEventDisabled, queue-length=1
      Event_DemEventParameter_ECU2_DTC04: provided-interface=DiagnosticMonitor
        provided-com-specs:
          operation=SetEventStatus, queue-length=1
          operation=SetEventStatusWithEnvdata, queue-length=1
          operation=ResetEventStatus, queue-length=1
          operation=PrestoreFreezeFrame, queue-length=1
          operation=ClearPrestoredFreezeFrame, queue-length=1
          operation=ResetEventDebounceStatus, queue-length=1
          operation=SetEventDisabled, queue-length=1
      Event_DemEventParameter_ECU2_DTC05: provided-interface=DiagnosticMonitor
        provided-com-specs:
          operation=SetEventStatus, queue-length=1
          operation=SetEventStatusWithEnvdata, queue-length=1
          operation=ResetEventStatus, queue-length=1
          operation=PrestoreFreezeFrame, queue-length=1
          operation=ClearPrestoredFreezeFrame, queue-length=1
          operation=ResetEventDebounceStatus, queue-length=1
          operation=SetEventDisabled, queue-length=1
      Event_DemEventParameter_ECU2_DTC06: provided-interface=DiagnosticMonitor
        provided-com-specs:
          operation=SetEventStatus, queue-length=1
          operation=SetEventStatusWithEnvdata, queue-length=1
          operation=ResetEventStatus, queue-length=1
          operation=PrestoreFreezeFrame, queue-length=1
          operation=ClearPrestoredFreezeFrame, queue-length=1
          operation=ResetEventDebounceStatus, queue-length=1
          operation=SetEventDisabled, queue-length=1
      Event_DemEventParameter_ECU2_DTC07: provided-interface=DiagnosticMonitor
        provided-com-specs:
          operation=SetEventStatus, queue-length=1
          operation=SetEventStatusWithEnvdata, queue-length=1
          operation=ResetEventStatus, queue-length=1
          operation=PrestoreFreezeFrame, queue-length=1
          operation=ClearPrestoredFreezeFrame, queue-length=1
          operation=ResetEventDebounceStatus, queue-length=1
          operation=SetEventDisabled, queue-length=1
      Event_DemEventParameter_ECU2_DTC08: provided-interface=DiagnosticMonitor
        provided-com-specs:
          operation=SetEventStatus, queue-length=1
          operation=SetEventStatusWithEnvdata, queue-length=1
          operation=ResetEventStatus, queue-length=1
          operation=PrestoreFreezeFrame, queue-length=1
          operation=ClearPrestoredFreezeFrame, queue-length=1
          operation=ResetEventDebounceStatus, queue-length=1
          operation=SetEventDisabled, queue-length=1
      Event_DemEventParameter_ECU2_DTC09: provided-interface=DiagnosticMonitor
        provided-com-specs:
          operation=SetEventStatus, queue-length=1
          operation=SetEventStatusWithEnvdata, queue-length=1
          operation=ResetEventStatus, queue-length=1
          operation=PrestoreFreezeFrame, queue-length=1
          operation=ClearPrestoredFreezeFrame, queue-length=1
          operation=ResetEventDebounceStatus, queue-length=1
          operation=SetEventDisabled, queue-length=1
      Event_DemEventParameter_ECU2_DTC10: provided-interface=DiagnosticMonitor
        provided-com-specs:
          operation=SetEventStatus, queue-length=1
          operation=SetEventStatusWithEnvdata, queue-length=1
          operation=ResetEventStatus, queue-length=1
          operation=PrestoreFreezeFrame, queue-length=1
          operation=ClearPrestoredFreezeFrame, queue-length=1
          operation=ResetEventDebounceStatus, queue-length=1
          operation=SetEventDisabled, queue-length=1
      Event_DemEventParameter_ECU2_DTC11: provided-interface=DiagnosticMonitor
        provided-com-specs:
          operation=SetEventStatus, queue-length=1
          operation=SetEventStatusWithEnvdata, queue-length=1
          operation=ResetEventStatus, queue-length=1
          operation=PrestoreFreezeFrame, queue-length=1
          operation=ClearPrestoredFreezeFrame, queue-length=1
          operation=ResetEventDebounceStatus, queue-length=1
          operation=SetEventDisabled, queue-length=1
      Event_DemEventParameter_ECU2_DTC12: provided-interface=DiagnosticMonitor
        provided-com-specs:
          operation=SetEventStatus, queue-length=1
          operation=SetEventStatusWithEnvdata, queue-length=1
          operation=ResetEventStatus, queue-length=1
          operation=PrestoreFreezeFrame, queue-length=1
          operation=ClearPrestoredFreezeFrame, queue-length=1
          operation=ResetEventDebounceStatus, queue-length=1
          operation=SetEventDisabled, queue-length=1
      Event_DemEventParameter_ECU2_DTC13: provided-interface=DiagnosticMonitor
        provided-com-specs:
          operation=SetEventStatus, queue-length=1
          operation=SetEventStatusWithEnvdata, queue-length=1
          operation=ResetEventStatus, queue-length=1
          operation=PrestoreFreezeFrame, queue-length=1
          operation=ClearPrestoredFreezeFrame, queue-length=1
          operation=ResetEventDebounceStatus, queue-length=1
          operation=SetEventDisabled, queue-length=1
      Event_DemEventParameter_ECU2_DTC14: provided-interface=DiagnosticMonitor
        provided-com-specs:
          operation=SetEventStatus, queue-length=1
          operation=SetEventStatusWithEnvdata, queue-length=1
          operation=ResetEventStatus, queue-length=1
          operation=PrestoreFreezeFrame, queue-length=1
          operation=ClearPrestoredFreezeFrame, queue-length=1
          operation=ResetEventDebounceStatus, queue-length=1
          operation=SetEventDisabled, queue-length=1
      Event_DemEventParameter_ECU2_DTC15: provided-interface=DiagnosticMonitor
        provided-com-specs:
          operation=SetEventStatus, queue-length=1
          operation=SetEventStatusWithEnvdata, queue-length=1
          operation=ResetEventStatus, queue-length=1
          operation=PrestoreFreezeFrame, queue-length=1
          operation=ClearPrestoredFreezeFrame, queue-length=1
          operation=ResetEventDebounceStatus, queue-length=1
          operation=SetEventDisabled, queue-length=1
      Event_DemEventParameter_ECU2_DTC16: provided-interface=DiagnosticMonitor
        provided-com-specs:
          operation=SetEventStatus, queue-length=1
          operation=SetEventStatusWithEnvdata, queue-length=1
          operation=ResetEventStatus, queue-length=1
          operation=PrestoreFreezeFrame, queue-length=1
          operation=ClearPrestoredFreezeFrame, queue-length=1
          operation=ResetEventDebounceStatus, queue-length=1
          operation=SetEventDisabled, queue-length=1
      Event_DemEventParameter_ECU2_DTC17: provided-interface=DiagnosticMonitor
        provided-com-specs:
          operation=SetEventStatus, queue-length=1
          operation=SetEventStatusWithEnvdata, queue-length=1
          operation=ResetEventStatus, queue-length=1
          operation=PrestoreFreezeFrame, queue-length=1
          operation=ClearPrestoredFreezeFrame, queue-length=1
          operation=ResetEventDebounceStatus, queue-length=1
          operation=SetEventDisabled, queue-length=1
      Event_DemEventParameter_ECU2_DTC18: provided-interface=DiagnosticMonitor
        provided-com-specs:
          operation=SetEventStatus, queue-length=1
          operation=SetEventStatusWithEnvdata, queue-length=1
          operation=ResetEventStatus, queue-length=1
          operation=PrestoreFreezeFrame, queue-length=1
          operation=ClearPrestoredFreezeFrame, queue-length=1
          operation=ResetEventDebounceStatus, queue-length=1
          operation=SetEventDisabled, queue-length=1
      Event_DemEventParameter_ECU2_DTC19: provided-interface=DiagnosticMonitor
        provided-com-specs:
          operation=SetEventStatus, queue-length=1
          operation=SetEventStatusWithEnvdata, queue-length=1
          operation=ResetEventStatus, queue-length=1
          operation=PrestoreFreezeFrame, queue-length=1
          operation=ClearPrestoredFreezeFrame, queue-length=1
          operation=ResetEventDebounceStatus, queue-length=1
          operation=SetEventDisabled, queue-length=1
      Event_DemEventParameter_ECU2_DTC20: provided-interface=DiagnosticMonitor
        provided-com-specs:
          operation=SetEventStatus, queue-length=1
          operation=SetEventStatusWithEnvdata, queue-length=1
          operation=ResetEventStatus, queue-length=1
          operation=PrestoreFreezeFrame, queue-length=1
          operation=ClearPrestoredFreezeFrame, queue-length=1
          operation=ResetEventDebounceStatus, queue-length=1
          operation=SetEventDisabled, queue-length=1
      Event_DemEventParameter_ECU2_DTC21: provided-interface=DiagnosticMonitor
        provided-com-specs:
          operation=SetEventStatus, queue-length=1
          operation=SetEventStatusWithEnvdata, queue-length=1
          operation=ResetEventStatus, queue-length=1
          operation=PrestoreFreezeFrame, queue-length=1
          operation=ClearPrestoredFreezeFrame, queue-length=1
          operation=ResetEventDebounceStatus, queue-length=1
          operation=SetEventDisabled, queue-length=1
      Event_DemEventParameter_ECU2_DTC22: provided-interface=DiagnosticMonitor
        provided-com-specs:
          operation=SetEventStatus, queue-length=1
          operation=SetEventStatusWithEnvdata, queue-length=1
          operation=ResetEventStatus, queue-length=1
          operation=PrestoreFreezeFrame, queue-length=1
          operation=ClearPrestoredFreezeFrame, queue-length=1
          operation=ResetEventDebounceStatus, queue-length=1
          operation=SetEventDisabled, queue-length=1
      Event_DemEventParameter_ECU2_DTC23: provided-interface=DiagnosticMonitor
        provided-com-specs:
          operation=SetEventStatus, queue-length=1
          operation=SetEventStatusWithEnvdata, queue-length=1
          operation=ResetEventStatus, queue-length=1
          operation=PrestoreFreezeFrame, queue-length=1
          operation=ClearPrestoredFreezeFrame, queue-length=1
          operation=ResetEventDebounceStatus, queue-length=1
          operation=SetEventDisabled, queue-length=1
      Event_DemEventParameter_ECU2_DTC24: provided-interface=DiagnosticMonitor
        provided-com-specs:
          operation=SetEventStatus, queue-length=1
          operation=SetEventStatusWithEnvdata, queue-length=1
          operation=ResetEventStatus, queue-length=1
          operation=PrestoreFreezeFrame, queue-length=1
          operation=ClearPrestoredFreezeFrame, queue-length=1
          operation=ResetEventDebounceStatus, queue-length=1
          operation=SetEventDisabled, queue-length=1
      Event_DemEventParameter_ECU2_DTC25: provided-interface=DiagnosticMonitor
        provided-com-specs:
          operation=SetEventStatus, queue-length=1
          operation=SetEventStatusWithEnvdata, queue-length=1
          operation=ResetEventStatus, queue-length=1
          operation=PrestoreFreezeFrame, queue-length=1
          operation=ClearPrestoredFreezeFrame, queue-length=1
          operation=ResetEventDebounceStatus, queue-length=1
          operation=SetEventDisabled, queue-length=1
      Event_DemEventParameter_ECU2_DTC26: provided-interface=DiagnosticMonitor
        provided-com-specs:
          operation=SetEventStatus, queue-length=1
          operation=SetEventStatusWithEnvdata, queue-length=1
          operation=ResetEventStatus, queue-length=1
          operation=PrestoreFreezeFrame, queue-length=1
          operation=ClearPrestoredFreezeFrame, queue-length=1
          operation=ResetEventDebounceStatus, queue-length=1
          operation=SetEventDisabled, queue-length=1
      Event_DemEventParameter_ECU2_DTC27: provided-interface=DiagnosticMonitor
        provided-com-specs:
          operation=SetEventStatus, queue-length=1
          operation=SetEventStatusWithEnvdata, queue-length=1
          operation=ResetEventStatus, queue-length=1
          operation=PrestoreFreezeFrame, queue-length=1
          operation=ClearPrestoredFreezeFrame, queue-length=1
          operation=ResetEventDebounceStatus, queue-length=1
          operation=SetEventDisabled, queue-length=1
      Event_DemEventParameter_ECU2_DTC28: provided-interface=DiagnosticMonitor
        provided-com-specs:
          operation=SetEventStatus, queue-length=1
          operation=SetEventStatusWithEnvdata, queue-length=1
          operation=ResetEventStatus, queue-length=1
          operation=PrestoreFreezeFrame, queue-length=1
          operation=ClearPrestoredFreezeFrame, queue-length=1
          operation=ResetEventDebounceStatus, queue-length=1
          operation=SetEventDisabled, queue-length=1
      Event_DemEventParameter_ECU2_DTC29: provided-interface=DiagnosticMonitor
        provided-com-specs:
          operation=SetEventStatus, queue-length=1
          operation=SetEventStatusWithEnvdata, queue-length=1
          operation=ResetEventStatus, queue-length=1
          operation=PrestoreFreezeFrame, queue-length=1
          operation=ClearPrestoredFreezeFrame, queue-length=1
          operation=ResetEventDebounceStatus, queue-length=1
          operation=SetEventDisabled, queue-length=1
      Event_DemEventParameter_ECU2_DTC30: provided-interface=DiagnosticMonitor
        provided-com-specs:
          operation=SetEventStatus, queue-length=1
          operation=SetEventStatusWithEnvdata, queue-length=1
          operation=ResetEventStatus, queue-length=1
          operation=PrestoreFreezeFrame, queue-length=1
          operation=ClearPrestoredFreezeFrame, queue-length=1
          operation=ResetEventDebounceStatus, queue-length=1
          operation=SetEventDisabled, queue-length=1
      Event_DemEventParameter_ECU2_DTC31: provided-interface=DiagnosticMonitor
        provided-com-specs:
          operation=SetEventStatus, queue-length=1
          operation=SetEventStatusWithEnvdata, queue-length=1
          operation=ResetEventStatus, queue-length=1
          operation=PrestoreFreezeFrame, queue-length=1
          operation=ClearPrestoredFreezeFrame, queue-length=1
          operation=ResetEventDebounceStatus, queue-length=1
          operation=SetEventDisabled, queue-length=1
      Event_DemEventParameter_ECU2_DTC32: provided-interface=DiagnosticMonitor
        provided-com-specs:
          operation=SetEventStatus, queue-length=1
          operation=SetEventStatusWithEnvdata, queue-length=1
          operation=ResetEventStatus, queue-length=1
          operation=PrestoreFreezeFrame, queue-length=1
          operation=ClearPrestoredFreezeFrame, queue-length=1
          operation=ResetEventDebounceStatus, queue-length=1
          operation=SetEventDisabled, queue-length=1
      Event_DemEventParameter_ECU2_DTC33: provided-interface=DiagnosticMonitor
        provided-com-specs:
          operation=SetEventStatus, queue-length=1
          operation=SetEventStatusWithEnvdata, queue-length=1
          operation=ResetEventStatus, queue-length=1
          operation=PrestoreFreezeFrame, queue-length=1
          operation=ClearPrestoredFreezeFrame, queue-length=1
          operation=ResetEventDebounceStatus, queue-length=1
          operation=SetEventDisabled, queue-length=1
      Event_DemEventParameter_ECU2_DTC34: provided-interface=DiagnosticMonitor
        provided-com-specs:
          operation=SetEventStatus, queue-length=1
          operation=SetEventStatusWithEnvdata, queue-length=1
          operation=ResetEventStatus, queue-length=1
          operation=PrestoreFreezeFrame, queue-length=1
          operation=ClearPrestoredFreezeFrame, queue-length=1
          operation=ResetEventDebounceStatus, queue-length=1
          operation=SetEventDisabled, queue-length=1
      Event_DemEventParameter_ECU2_DTC35: provided-interface=DiagnosticMonitor
        provided-com-specs:
          operation=SetEventStatus, queue-length=1
          operation=SetEventStatusWithEnvdata, queue-length=1
          operation=ResetEventStatus, queue-length=1
          operation=PrestoreFreezeFrame, queue-length=1
          operation=ClearPrestoredFreezeFrame, queue-length=1
          operation=ResetEventDebounceStatus, queue-length=1
          operation=SetEventDisabled, queue-length=1
      Event_DemEventParameter_ECU2_DTC36: provided-interface=DiagnosticMonitor
        provided-com-specs:
          operation=SetEventStatus, queue-length=1
          operation=SetEventStatusWithEnvdata, queue-length=1
          operation=ResetEventStatus, queue-length=1
          operation=PrestoreFreezeFrame, queue-length=1
          operation=ClearPrestoredFreezeFrame, queue-length=1
          operation=ResetEventDebounceStatus, queue-length=1
          operation=SetEventDisabled, queue-length=1
      Event_DemEventParameter_ECU2_DTC37: provided-interface=DiagnosticMonitor
        provided-com-specs:
          operation=SetEventStatus, queue-length=1
          operation=SetEventStatusWithEnvdata, queue-length=1
          operation=ResetEventStatus, queue-length=1
          operation=PrestoreFreezeFrame, queue-length=1
          operation=ClearPrestoredFreezeFrame, queue-length=1
          operation=ResetEventDebounceStatus, queue-length=1
          operation=SetEventDisabled, queue-length=1
      Event_DemEventParameter_ECU2_DTC38: provided-interface=DiagnosticMonitor
        provided-com-specs:
          operation=SetEventStatus, queue-length=1
          operation=SetEventStatusWithEnvdata, queue-length=1
          operation=ResetEventStatus, queue-length=1
          operation=PrestoreFreezeFrame, queue-length=1
          operation=ClearPrestoredFreezeFrame, queue-length=1
          operation=ResetEventDebounceStatus, queue-length=1
          operation=SetEventDisabled, queue-length=1
      Event_DemEventParameter_ECU2_DTC39: provided-interface=DiagnosticMonitor
        provided-com-specs:
          operation=SetEventStatus, queue-length=1
          operation=SetEventStatusWithEnvdata, queue-length=1
          operation=ResetEventStatus, queue-length=1
          operation=PrestoreFreezeFrame, queue-length=1
          operation=ClearPrestoredFreezeFrame, queue-length=1
          operation=ResetEventDebounceStatus, queue-length=1
          operation=SetEventDisabled, queue-length=1
      Event_DemEventParameter_ECU2_DTC40: provided-interface=DiagnosticMonitor
        provided-com-specs:
          operation=SetEventStatus, queue-length=1
          operation=SetEventStatusWithEnvdata, queue-length=1
          operation=ResetEventStatus, queue-length=1
          operation=PrestoreFreezeFrame, queue-length=1
          operation=ClearPrestoredFreezeFrame, queue-length=1
          operation=ResetEventDebounceStatus, queue-length=1
          operation=SetEventDisabled, queue-length=1
      Event_DemEventParameter_ECU2_DTC41: provided-interface=DiagnosticMonitor
        provided-com-specs:
          operation=SetEventStatus, queue-length=1
          operation=SetEventStatusWithEnvdata, queue-length=1
          operation=ResetEventStatus, queue-length=1
          operation=PrestoreFreezeFrame, queue-length=1
          operation=ClearPrestoredFreezeFrame, queue-length=1
          operation=ResetEventDebounceStatus, queue-length=1
          operation=SetEventDisabled, queue-length=1
      Event_DemEventParameter_ECU2_DTC42: provided-interface=DiagnosticMonitor
        provided-com-specs:
          operation=SetEventStatus, queue-length=1
          operation=SetEventStatusWithEnvdata, queue-length=1
          operation=ResetEventStatus, queue-length=1
          operation=PrestoreFreezeFrame, queue-length=1
          operation=ClearPrestoredFreezeFrame, queue-length=1
          operation=ResetEventDebounceStatus, queue-length=1
          operation=SetEventDisabled, queue-length=1
      Event_DemEventParameter_ECU2_DTC43: provided-interface=DiagnosticMonitor
        provided-com-specs:
          operation=SetEventStatus, queue-length=1
          operation=SetEventStatusWithEnvdata, queue-length=1
          operation=ResetEventStatus, queue-length=1
          operation=PrestoreFreezeFrame, queue-length=1
          operation=ClearPrestoredFreezeFrame, queue-length=1
          operation=ResetEventDebounceStatus, queue-length=1
          operation=SetEventDisabled, queue-length=1
      Event_DemEventParameter_ECU2_DTC44: provided-interface=DiagnosticMonitor
        provided-com-specs:
          operation=SetEventStatus, queue-length=1
          operation=SetEventStatusWithEnvdata, queue-length=1
          operation=ResetEventStatus, queue-length=1
          operation=PrestoreFreezeFrame, queue-length=1
          operation=ClearPrestoredFreezeFrame, queue-length=1
          operation=ResetEventDebounceStatus, queue-length=1
          operation=SetEventDisabled, queue-length=1
      Event_DemEventParameter_ECU2_DTC45: provided-interface=DiagnosticMonitor
        provided-com-specs:
          operation=SetEventStatus, queue-length=1
          operation=SetEventStatusWithEnvdata, queue-length=1
          operation=ResetEventStatus, queue-length=1
          operation=PrestoreFreezeFrame, queue-length=1
          operation=ClearPrestoredFreezeFrame, queue-length=1
          operation=ResetEventDebounceStatus, queue-length=1
          operation=SetEventDisabled, queue-length=1
      Event_DemEventParameter_ECU2_DTC46: provided-interface=DiagnosticMonitor
        provided-com-specs:
          operation=SetEventStatus, queue-length=1
          operation=SetEventStatusWithEnvdata, queue-length=1
          operation=ResetEventStatus, queue-length=1
          operation=PrestoreFreezeFrame, queue-length=1
          operation=ClearPrestoredFreezeFrame, queue-length=1
          operation=ResetEventDebounceStatus, queue-length=1
          operation=SetEventDisabled, queue-length=1
      Event_DemEventParameter_ECU2_DTC47: provided-interface=DiagnosticMonitor
        provided-com-specs:
          operation=SetEventStatus, queue-length=1
          operation=SetEventStatusWithEnvdata, queue-length=1
          operation=ResetEventStatus, queue-length=1
          operation=PrestoreFreezeFrame, queue-length=1
          operation=ClearPrestoredFreezeFrame, queue-length=1
          operation=ResetEventDebounceStatus, queue-length=1
          operation=SetEventDisabled, queue-length=1
      Event_DemEventParameter_ECU2_DTC48: provided-interface=DiagnosticMonitor
        provided-com-specs:
          operation=SetEventStatus, queue-length=1
          operation=SetEventStatusWithEnvdata, queue-length=1
          operation=ResetEventStatus, queue-length=1
          operation=PrestoreFreezeFrame, queue-length=1
          operation=ClearPrestoredFreezeFrame, queue-length=1
          operation=ResetEventDebounceStatus, queue-length=1
          operation=SetEventDisabled, queue-length=1
      Event_DemEventParameter_ECU2_DTC49: provided-interface=DiagnosticMonitor
        provided-com-specs:
          operation=SetEventStatus, queue-length=1
          operation=SetEventStatusWithEnvdata, queue-length=1
          operation=ResetEventStatus, queue-length=1
          operation=PrestoreFreezeFrame, queue-length=1
          operation=ClearPrestoredFreezeFrame, queue-length=1
          operation=ResetEventDebounceStatus, queue-length=1
          operation=SetEventDisabled, queue-length=1
      Event_DemEventParameter_ECU2_DTC50: provided-interface=DiagnosticMonitor
        provided-com-specs:
          operation=SetEventStatus, queue-length=1
          operation=SetEventStatusWithEnvdata, queue-length=1
          operation=ResetEventStatus, queue-length=1
          operation=PrestoreFreezeFrame, queue-length=1
          operation=ClearPrestoredFreezeFrame, queue-length=1
          operation=ResetEventDebounceStatus, queue-length=1
          operation=SetEventDisabled, queue-length=1
      Event_DemEventParameter_ECU2_DTC51: provided-interface=DiagnosticMonitor
        provided-com-specs:
          operation=SetEventStatus, queue-length=1
          operation=SetEventStatusWithEnvdata, queue-length=1
          operation=ResetEventStatus, queue-length=1
          operation=PrestoreFreezeFrame, queue-length=1
          operation=ClearPrestoredFreezeFrame, queue-length=1
          operation=ResetEventDebounceStatus, queue-length=1
          operation=SetEventDisabled, queue-length=1
      Event_DemEventParameter_ECU2_DTC52: provided-interface=DiagnosticMonitor
        provided-com-specs:
          operation=SetEventStatus, queue-length=1
          operation=SetEventStatusWithEnvdata, queue-length=1
          operation=ResetEventStatus, queue-length=1
          operation=PrestoreFreezeFrame, queue-length=1
          operation=ClearPrestoredFreezeFrame, queue-length=1
          operation=ResetEventDebounceStatus, queue-length=1
          operation=SetEventDisabled, queue-length=1
      Event_DemEventParameter_ECU2_DTC53: provided-interface=DiagnosticMonitor
        provided-com-specs:
          operation=SetEventStatus, queue-length=1
          operation=SetEventStatusWithEnvdata, queue-length=1
          operation=ResetEventStatus, queue-length=1
          operation=PrestoreFreezeFrame, queue-length=1
          operation=ClearPrestoredFreezeFrame, queue-length=1
          operation=ResetEventDebounceStatus, queue-length=1
          operation=SetEventDisabled, queue-length=1
      Event_DemEventParameter_ECU2_DTC54: provided-interface=DiagnosticMonitor
        provided-com-specs:
          operation=SetEventStatus, queue-length=1
          operation=SetEventStatusWithEnvdata, queue-length=1
          operation=ResetEventStatus, queue-length=1
          operation=PrestoreFreezeFrame, queue-length=1
          operation=ClearPrestoredFreezeFrame, queue-length=1
          operation=ResetEventDebounceStatus, queue-length=1
          operation=SetEventDisabled, queue-length=1
      Event_DemEventParameter_ECU2_DTC55: provided-interface=DiagnosticMonitor
        provided-com-specs:
          operation=SetEventStatus, queue-length=1
          operation=SetEventStatusWithEnvdata, queue-length=1
          operation=ResetEventStatus, queue-length=1
          operation=PrestoreFreezeFrame, queue-length=1
          operation=ClearPrestoredFreezeFrame, queue-length=1
          operation=ResetEventDebounceStatus, queue-length=1
          operation=SetEventDisabled, queue-length=1
      Event_DemEventParameter_ECU2_DTC56: provided-interface=DiagnosticMonitor
        provided-com-specs:
          operation=SetEventStatus, queue-length=1
          operation=SetEventStatusWithEnvdata, queue-length=1
          operation=ResetEventStatus, queue-length=1
          operation=PrestoreFreezeFrame, queue-length=1
          operation=ClearPrestoredFreezeFrame, queue-length=1
          operation=ResetEventDebounceStatus, queue-length=1
          operation=SetEventDisabled, queue-length=1
      Event_DemEventParameter_ECU2_DTC57: provided-interface=DiagnosticMonitor
        provided-com-specs:
          operation=SetEventStatus, queue-length=1
          operation=SetEventStatusWithEnvdata, queue-length=1
          operation=ResetEventStatus, queue-length=1
          operation=PrestoreFreezeFrame, queue-length=1
          operation=ClearPrestoredFreezeFrame, queue-length=1
          operation=ResetEventDebounceStatus, queue-length=1
          operation=SetEventDisabled, queue-length=1
      Event_DemEventParameter_ECU2_DTC58: provided-interface=DiagnosticMonitor
        provided-com-specs:
          operation=SetEventStatus, queue-length=1
          operation=SetEventStatusWithEnvdata, queue-length=1
          operation=ResetEventStatus, queue-length=1
          operation=PrestoreFreezeFrame, queue-length=1
          operation=ClearPrestoredFreezeFrame, queue-length=1
          operation=ResetEventDebounceStatus, queue-length=1
          operation=SetEventDisabled, queue-length=1
      Event_DemEventParameter_ECU2_DTC59: provided-interface=DiagnosticMonitor
        provided-com-specs:
          operation=SetEventStatus, queue-length=1
          operation=SetEventStatusWithEnvdata, queue-length=1
          operation=ResetEventStatus, queue-length=1
          operation=PrestoreFreezeFrame, queue-length=1
          operation=ClearPrestoredFreezeFrame, queue-length=1
          operation=ResetEventDebounceStatus, queue-length=1
          operation=SetEventDisabled, queue-length=1
      Event_DemEventParameter_ECU2_DTC60: provided-interface=DiagnosticMonitor
        provided-com-specs:
          operation=SetEventStatus, queue-length=1
          operation=SetEventStatusWithEnvdata, queue-length=1
          operation=ResetEventStatus, queue-length=1
          operation=PrestoreFreezeFrame, queue-length=1
          operation=ClearPrestoredFreezeFrame, queue-length=1
          operation=ResetEventDebounceStatus, queue-length=1
          operation=SetEventDisabled, queue-length=1
      Event_DemEventParameter_ECU2_DTC61: provided-interface=DiagnosticMonitor
        provided-com-specs:
          operation=SetEventStatus, queue-length=1
          operation=SetEventStatusWithEnvdata, queue-length=1
          operation=ResetEventStatus, queue-length=1
          operation=PrestoreFreezeFrame, queue-length=1
          operation=ClearPrestoredFreezeFrame, queue-length=1
          operation=ResetEventDebounceStatus, queue-length=1
          operation=SetEventDisabled, queue-length=1
      Event_DemEventParameter_ECU2_DTC62: provided-interface=DiagnosticMonitor
        provided-com-specs:
          operation=SetEventStatus, queue-length=1
          operation=SetEventStatusWithEnvdata, queue-length=1
          operation=ResetEventStatus, queue-length=1
          operation=PrestoreFreezeFrame, queue-length=1
          operation=ClearPrestoredFreezeFrame, queue-length=1
          operation=ResetEventDebounceStatus, queue-length=1
          operation=SetEventDisabled, queue-length=1
      Event_DemEventParameter_ECU2_DTC63: provided-interface=DiagnosticMonitor
        provided-com-specs:
          operation=SetEventStatus, queue-length=1
          operation=SetEventStatusWithEnvdata, queue-length=1
          operation=ResetEventStatus, queue-length=1
          operation=PrestoreFreezeFrame, queue-length=1
          operation=ClearPrestoredFreezeFrame, queue-length=1
          operation=ResetEventDebounceStatus, queue-length=1
          operation=SetEventDisabled, queue-length=1
      Event_DemEventParameter_ECU2_DTC64: provided-interface=DiagnosticMonitor
        provided-com-specs:
          operation=SetEventStatus, queue-length=1
          operation=SetEventStatusWithEnvdata, queue-length=1
          operation=ResetEventStatus, queue-length=1
          operation=PrestoreFreezeFrame, queue-length=1
          operation=ClearPrestoredFreezeFrame, queue-length=1
          operation=ResetEventDebounceStatus, queue-length=1
          operation=SetEventDisabled, queue-length=1
      Event_DemEventParameter_ECU2_DTC65: provided-interface=DiagnosticMonitor
        provided-com-specs:
          operation=SetEventStatus, queue-length=1
          operation=SetEventStatusWithEnvdata, queue-length=1
          operation=ResetEventStatus, queue-length=1
          operation=PrestoreFreezeFrame, queue-length=1
          operation=ClearPrestoredFreezeFrame, queue-length=1
          operation=ResetEventDebounceStatus, queue-length=1
          operation=SetEventDisabled, queue-length=1
      Event_DemEventParameter_ECU2_DTC66: provided-interface=DiagnosticMonitor
        provided-com-specs:
          operation=SetEventStatus, queue-length=1
          operation=SetEventStatusWithEnvdata, queue-length=1
          operation=ResetEventStatus, queue-length=1
          operation=PrestoreFreezeFrame, queue-length=1
          operation=ClearPrestoredFreezeFrame, queue-length=1
          operation=ResetEventDebounceStatus, queue-length=1
          operation=SetEventDisabled, queue-length=1
      Event_DemEventParameter_ECU2_DTC67: provided-interface=DiagnosticMonitor
        provided-com-specs:
          operation=SetEventStatus, queue-length=1
          operation=SetEventStatusWithEnvdata, queue-length=1
          operation=ResetEventStatus, queue-length=1
          operation=PrestoreFreezeFrame, queue-length=1
          operation=ClearPrestoredFreezeFrame, queue-length=1
          operation=ResetEventDebounceStatus, queue-length=1
          operation=SetEventDisabled, queue-length=1
      Event_DemEventParameter_ECU2_DTC68: provided-interface=DiagnosticMonitor
        provided-com-specs:
          operation=SetEventStatus, queue-length=1
          operation=SetEventStatusWithEnvdata, queue-length=1
          operation=ResetEventStatus, queue-length=1
          operation=PrestoreFreezeFrame, queue-length=1
          operation=ClearPrestoredFreezeFrame, queue-length=1
          operation=ResetEventDebounceStatus, queue-length=1
          operation=SetEventDisabled, queue-length=1
      Event_DemEventParameter_ECU2_DTC69: provided-interface=DiagnosticMonitor
        provided-com-specs:
          operation=SetEventStatus, queue-length=1
          operation=SetEventStatusWithEnvdata, queue-length=1
          operation=ResetEventStatus, queue-length=1
          operation=PrestoreFreezeFrame, queue-length=1
          operation=ClearPrestoredFreezeFrame, queue-length=1
          operation=ResetEventDebounceStatus, queue-length=1
          operation=SetEventDisabled, queue-length=1
      Event_DemEventParameter_ECU2_DTC70: provided-interface=DiagnosticMonitor
        provided-com-specs:
          operation=SetEventStatus, queue-length=1
          operation=SetEventStatusWithEnvdata, queue-length=1
          operation=ResetEventStatus, queue-length=1
          operation=PrestoreFreezeFrame, queue-length=1
          operation=ClearPrestoredFreezeFrame, queue-length=1
          operation=ResetEventDebounceStatus, queue-length=1
          operation=SetEventDisabled, queue-length=1
      Event_DemEventParameter_ECU2_DTC71: provided-interface=DiagnosticMonitor
        provided-com-specs:
          operation=SetEventStatus, queue-length=1
          operation=SetEventStatusWithEnvdata, queue-length=1
          operation=ResetEventStatus, queue-length=1
          operation=PrestoreFreezeFrame, queue-length=1
          operation=ClearPrestoredFreezeFrame, queue-length=1
          operation=ResetEventDebounceStatus, queue-length=1
          operation=SetEventDisabled, queue-length=1
      Event_DemEventParameter_ECU2_DTC72: provided-interface=DiagnosticMonitor
        provided-com-specs:
          operation=SetEventStatus, queue-length=1
          operation=SetEventStatusWithEnvdata, queue-length=1
          operation=ResetEventStatus, queue-length=1
          operation=PrestoreFreezeFrame, queue-length=1
          operation=ClearPrestoredFreezeFrame, queue-length=1
          operation=ResetEventDebounceStatus, queue-length=1
          operation=SetEventDisabled, queue-length=1
      Event_DemEventParameter_ECU2_DTC73: provided-interface=DiagnosticMonitor
        provided-com-specs:
          operation=SetEventStatus, queue-length=1
          operation=SetEventStatusWithEnvdata, queue-length=1
          operation=ResetEventStatus, queue-length=1
          operation=PrestoreFreezeFrame, queue-length=1
          operation=ClearPrestoredFreezeFrame, queue-length=1
          operation=ResetEventDebounceStatus, queue-length=1
          operation=SetEventDisabled, queue-length=1
      Event_DemEventParameter_ECU2_DTC74: provided-interface=DiagnosticMonitor
        provided-com-specs:
          operation=SetEventStatus, queue-length=1
          operation=SetEventStatusWithEnvdata, queue-length=1
          operation=ResetEventStatus, queue-length=1
          operation=PrestoreFreezeFrame, queue-length=1
          operation=ClearPrestoredFreezeFrame, queue-length=1
          operation=ResetEventDebounceStatus, queue-length=1
          operation=SetEventDisabled, queue-length=1
      Event_DemEventParameter_ECU2_DTC75: provided-interface=DiagnosticMonitor
        provided-com-specs:
          operation=SetEventStatus, queue-length=1
          operation=SetEventStatusWithEnvdata, queue-length=1
          operation=ResetEventStatus, queue-length=1
          operation=PrestoreFreezeFrame, queue-length=1
          operation=ClearPrestoredFreezeFrame, queue-length=1
          operation=ResetEventDebounceStatus, queue-length=1
          operation=SetEventDisabled, queue-length=1
      Event_DemEventParameter_ECU2_DTC76: provided-interface=DiagnosticMonitor
        provided-com-specs:
          operation=SetEventStatus, queue-length=1
          operation=SetEventStatusWithEnvdata, queue-length=1
          operation=ResetEventStatus, queue-length=1
          operation=PrestoreFreezeFrame, queue-length=1
          operation=ClearPrestoredFreezeFrame, queue-length=1
          operation=ResetEventDebounceStatus, queue-length=1
          operation=SetEventDisabled, queue-length=1
      Event_DemEventParameter_ECU2_DTC77: provided-interface=DiagnosticMonitor
        provided-com-specs:
          operation=SetEventStatus, queue-length=1
          operation=SetEventStatusWithEnvdata, queue-length=1
          operation=ResetEventStatus, queue-length=1
          operation=PrestoreFreezeFrame, queue-length=1
          operation=ClearPrestoredFreezeFrame, queue-length=1
          operation=ResetEventDebounceStatus, queue-length=1
          operation=SetEventDisabled, queue-length=1
      Event_DemEventParameter_ECU2_DTC78: provided-interface=DiagnosticMonitor
        provided-com-specs:
          operation=SetEventStatus, queue-length=1
          operation=SetEventStatusWithEnvdata, queue-length=1
          operation=ResetEventStatus, queue-length=1
          operation=PrestoreFreezeFrame, queue-length=1
          operation=ClearPrestoredFreezeFrame, queue-length=1
          operation=ResetEventDebounceStatus, queue-length=1
          operation=SetEventDisabled, queue-length=1
      Event_DemEventParameter_ECU2_DTC79: provided-interface=DiagnosticMonitor
        provided-com-specs:
          operation=SetEventStatus, queue-length=1
          operation=SetEventStatusWithEnvdata, queue-length=1
          operation=ResetEventStatus, queue-length=1
          operation=PrestoreFreezeFrame, queue-length=1
          operation=ClearPrestoredFreezeFrame, queue-length=1
          operation=ResetEventDebounceStatus, queue-length=1
          operation=SetEventDisabled, queue-length=1
      Event_DemEventParameter_ECU2_DTC80: provided-interface=DiagnosticMonitor
        provided-com-specs:
          operation=SetEventStatus, queue-length=1
          operation=SetEventStatusWithEnvdata, queue-length=1
          operation=ResetEventStatus, queue-length=1
          operation=PrestoreFreezeFrame, queue-length=1
          operation=ClearPrestoredFreezeFrame, queue-length=1
          operation=ResetEventDebounceStatus, queue-length=1
          operation=SetEventDisabled, queue-length=1
      Event_DemEventParameter_ECU2_DTC81: provided-interface=DiagnosticMonitor
        provided-com-specs:
          operation=SetEventStatus, queue-length=1
          operation=SetEventStatusWithEnvdata, queue-length=1
          operation=ResetEventStatus, queue-length=1
          operation=PrestoreFreezeFrame, queue-length=1
          operation=ClearPrestoredFreezeFrame, queue-length=1
          operation=ResetEventDebounceStatus, queue-length=1
          operation=SetEventDisabled, queue-length=1
      Event_DemEventParameter_ECU2_DTC82: provided-interface=DiagnosticMonitor
        provided-com-specs:
          operation=SetEventStatus, queue-length=1
          operation=SetEventStatusWithEnvdata, queue-length=1
          operation=ResetEventStatus, queue-length=1
          operation=PrestoreFreezeFrame, queue-length=1
          operation=ClearPrestoredFreezeFrame, queue-length=1
          operation=ResetEventDebounceStatus, queue-length=1
          operation=SetEventDisabled, queue-length=1
      Event_DemEventParameter_ECU2_DTC83: provided-interface=DiagnosticMonitor
        provided-com-specs:
          operation=SetEventStatus, queue-length=1
          operation=SetEventStatusWithEnvdata, queue-length=1
          operation=ResetEventStatus, queue-length=1
          operation=PrestoreFreezeFrame, queue-length=1
          operation=ClearPrestoredFreezeFrame, queue-length=1
          operation=ResetEventDebounceStatus, queue-length=1
          operation=SetEventDisabled, queue-length=1
      Event_DemEventParameter_ECU2_DTC84: provided-interface=DiagnosticMonitor
        provided-com-specs:
          operation=SetEventStatus, queue-length=1
          operation=SetEventStatusWithEnvdata, queue-length=1
          operation=ResetEventStatus, queue-length=1
          operation=PrestoreFreezeFrame, queue-length=1
          operation=ClearPrestoredFreezeFrame, queue-length=1
          operation=ResetEventDebounceStatus, queue-length=1
          operation=SetEventDisabled, queue-length=1
      Event_DemEventParameter_ECU2_DTC85: provided-interface=DiagnosticMonitor
        provided-com-specs:
          operation=SetEventStatus, queue-length=1
          operation=SetEventStatusWithEnvdata, queue-length=1
          operation=ResetEventStatus, queue-length=1
          operation=PrestoreFreezeFrame, queue-length=1
          operation=ClearPrestoredFreezeFrame, queue-length=1
          operation=ResetEventDebounceStatus, queue-length=1
          operation=SetEventDisabled, queue-length=1
      Event_DemEventParameter_ECU2_DTC86: provided-interface=DiagnosticMonitor
        provided-com-specs:
          operation=SetEventStatus, queue-length=1
          operation=SetEventStatusWithEnvdata, queue-length=1
          operation=ResetEventStatus, queue-length=1
          operation=PrestoreFreezeFrame, queue-length=1
          operation=ClearPrestoredFreezeFrame, queue-length=1
          operation=ResetEventDebounceStatus, queue-length=1
          operation=SetEventDisabled, queue-length=1
      Event_DemEventParameter_ECU2_DTC87: provided-interface=DiagnosticMonitor
        provided-com-specs:
          operation=SetEventStatus, queue-length=1
          operation=SetEventStatusWithEnvdata, queue-length=1
          operation=ResetEventStatus, queue-length=1
          operation=PrestoreFreezeFrame, queue-length=1
          operation=ClearPrestoredFreezeFrame, queue-length=1
          operation=ResetEventDebounceStatus, queue-length=1
          operation=SetEventDisabled, queue-length=1
      Event_DemEventParameter_ECU2_DTC88: provided-interface=DiagnosticMonitor
        provided-com-specs:
          operation=SetEventStatus, queue-length=1
          operation=SetEventStatusWithEnvdata, queue-length=1
          operation=ResetEventStatus, queue-length=1
          operation=PrestoreFreezeFrame, queue-length=1
          operation=ClearPrestoredFreezeFrame, queue-length=1
          operation=ResetEventDebounceStatus, queue-length=1
          operation=SetEventDisabled, queue-length=1
      Event_DemEventParameter_ECU2_DTC89: provided-interface=DiagnosticMonitor
        provided-com-specs:
          operation=SetEventStatus, queue-length=1
          operation=SetEventStatusWithEnvdata, queue-length=1
          operation=ResetEventStatus, queue-length=1
          operation=PrestoreFreezeFrame, queue-length=1
          operation=ClearPrestoredFreezeFrame, queue-length=1
          operation=ResetEventDebounceStatus, queue-length=1
          operation=SetEventDisabled, queue-length=1
      Event_DemEventParameter_ECU2_DTC90: provided-interface=DiagnosticMonitor
        provided-com-specs:
          operation=SetEventStatus, queue-length=1
          operation=SetEventStatusWithEnvdata, queue-length=1
          operation=ResetEventStatus, queue-length=1
          operation=PrestoreFreezeFrame, queue-length=1
          operation=ClearPrestoredFreezeFrame, queue-length=1
          operation=ResetEventDebounceStatus, queue-length=1
          operation=SetEventDisabled, queue-length=1
      Event_DemEventParameter_ECU2_DTC91: provided-interface=DiagnosticMonitor
        provided-com-specs:
          operation=SetEventStatus, queue-length=1
          operation=SetEventStatusWithEnvdata, queue-length=1
          operation=ResetEventStatus, queue-length=1
          operation=PrestoreFreezeFrame, queue-length=1
          operation=ClearPrestoredFreezeFrame, queue-length=1
          operation=ResetEventDebounceStatus, queue-length=1
          operation=SetEventDisabled, queue-length=1
      Event_DemEventParameter_ECU2_DTC92: provided-interface=DiagnosticMonitor
        provided-com-specs:
          operation=SetEventStatus, queue-length=1
          operation=SetEventStatusWithEnvdata, queue-length=1
          operation=ResetEventStatus, queue-length=1
          operation=PrestoreFreezeFrame, queue-length=1
          operation=ClearPrestoredFreezeFrame, queue-length=1
          operation=ResetEventDebounceStatus, queue-length=1
          operation=SetEventDisabled, queue-length=1
      Event_DemEventParameter_ECU2_DTC93: provided-interface=DiagnosticMonitor
        provided-com-specs:
          operation=SetEventStatus, queue-length=1
          operation=SetEventStatusWithEnvdata, queue-length=1
          operation=ResetEventStatus, queue-length=1
          operation=PrestoreFreezeFrame, queue-length=1
          operation=ClearPrestoredFreezeFrame, queue-length=1
          operation=ResetEventDebounceStatus, queue-length=1
          operation=SetEventDisabled, queue-length=1
      Event_DemEventParameter_ECU2_DTC94: provided-interface=DiagnosticMonitor
        provided-com-specs:
          operation=SetEventStatus, queue-length=1
          operation=SetEventStatusWithEnvdata, queue-length=1
          operation=ResetEventStatus, queue-length=1
          operation=PrestoreFreezeFrame, queue-length=1
          operation=ClearPrestoredFreezeFrame, queue-length=1
          operation=ResetEventDebounceStatus, queue-length=1
          operation=SetEventDisabled, queue-length=1
      Event_DemEventParameter_ECU2_DTC95: provided-interface=DiagnosticMonitor
        provided-com-specs:
          operation=SetEventStatus, queue-length=1
          operation=SetEventStatusWithEnvdata, queue-length=1
          operation=ResetEventStatus, queue-length=1
          operation=PrestoreFreezeFrame, queue-length=1
          operation=ClearPrestoredFreezeFrame, queue-length=1
          operation=ResetEventDebounceStatus, queue-length=1
          operation=SetEventDisabled, queue-length=1
      Event_DemEventParameter_ECU2_DTC96: provided-interface=DiagnosticMonitor
        provided-com-specs:
          operation=SetEventStatus, queue-length=1
          operation=SetEventStatusWithEnvdata, queue-length=1
          operation=ResetEventStatus, queue-length=1
          operation=PrestoreFreezeFrame, queue-length=1
          operation=ClearPrestoredFreezeFrame, queue-length=1
          operation=ResetEventDebounceStatus, queue-length=1
          operation=SetEventDisabled, queue-length=1
      Event_DemEventParameter_ECU2_DTC97: provided-interface=DiagnosticMonitor
        provided-com-specs:
          operation=SetEventStatus, queue-length=1
          operation=SetEventStatusWithEnvdata, queue-length=1
          operation=ResetEventStatus, queue-length=1
          operation=PrestoreFreezeFrame, queue-length=1
          operation=ClearPrestoredFreezeFrame, queue-length=1
          operation=ResetEventDebounceStatus, queue-length=1
          operation=SetEventDisabled, queue-length=1
      Event_DemEventParameter_ECU2_DTC98: provided-interface=DiagnosticMonitor
        provided-com-specs:
          operation=SetEventStatus, queue-length=1
          operation=SetEventStatusWithEnvdata, queue-length=1
          operation=ResetEventStatus, queue-length=1
          operation=PrestoreFreezeFrame, queue-length=1
          operation=ClearPrestoredFreezeFrame, queue-length=1
          operation=ResetEventDebounceStatus, queue-length=1
          operation=SetEventDisabled, queue-length=1
      Event_DemEventParameter_ECU2_DTC99: provided-interface=DiagnosticMonitor
        provided-com-specs:
          operation=SetEventStatus, queue-length=1
          operation=SetEventStatusWithEnvdata, queue-length=1
          operation=ResetEventStatus, queue-length=1
          operation=PrestoreFreezeFrame, queue-length=1
          operation=ClearPrestoredFreezeFrame, queue-length=1
          operation=ResetEventDebounceStatus, queue-length=1
          operation=SetEventDisabled, queue-length=1
      Event_DemEventParameter_ECU3_DTC00: provided-interface=DiagnosticMonitor
        provided-com-specs:
          operation=SetEventStatus, queue-length=1
          operation=SetEventStatusWithEnvdata, queue-length=1
          operation=ResetEventStatus, queue-length=1
          operation=PrestoreFreezeFrame, queue-length=1
          operation=ClearPrestoredFreezeFrame, queue-length=1
          operation=ResetEventDebounceStatus, queue-length=1
          operation=SetEventDisabled, queue-length=1
      Event_DemEventParameter_ECU3_DTC01: provided-interface=DiagnosticMonitor
        provided-com-specs:
          operation=SetEventStatus, queue-length=1
          operation=SetEventStatusWithEnvdata, queue-length=1
          operation=ResetEventStatus, queue-length=1
          operation=PrestoreFreezeFrame, queue-length=1
          operation=ClearPrestoredFreezeFrame, queue-length=1
          operation=ResetEventDebounceStatus, queue-length=1
          operation=SetEventDisabled, queue-length=1
      Event_DemEventParameter_ECU3_DTC02: provided-interface=DiagnosticMonitor
        provided-com-specs:
          operation=SetEventStatus, queue-length=1
          operation=SetEventStatusWithEnvdata, queue-length=1
          operation=ResetEventStatus, queue-length=1
          operation=PrestoreFreezeFrame, queue-length=1
          operation=ClearPrestoredFreezeFrame, queue-length=1
          operation=ResetEventDebounceStatus, queue-length=1
          operation=SetEventDisabled, queue-length=1
      Event_DemEventParameter_ECU3_DTC03: provided-interface=DiagnosticMonitor
        provided-com-specs:
          operation=SetEventStatus, queue-length=1
          operation=SetEventStatusWithEnvdata, queue-length=1
          operation=ResetEventStatus, queue-length=1
          operation=PrestoreFreezeFrame, queue-length=1
          operation=ClearPrestoredFreezeFrame, queue-length=1
          operation=ResetEventDebounceStatus, queue-length=1
          operation=SetEventDisabled, queue-length=1
      Event_DemEventParameter_ECU3_DTC04: provided-interface=DiagnosticMonitor
        provided-com-specs:
          operation=SetEventStatus, queue-length=1
          operation=SetEventStatusWithEnvdata, queue-length=1
          operation=ResetEventStatus, queue-length=1
          operation=PrestoreFreezeFrame, queue-length=1
          operation=ClearPrestoredFreezeFrame, queue-length=1
          operation=ResetEventDebounceStatus, queue-length=1
          operation=SetEventDisabled, queue-length=1
      Event_DemEventParameter_ECU3_DTC05: provided-interface=DiagnosticMonitor
        provided-com-specs:
          operation=SetEventStatus, queue-length=1
          operation=SetEventStatusWithEnvdata, queue-length=1
          operation=ResetEventStatus, queue-length=1
          operation=PrestoreFreezeFrame, queue-length=1
          operation=ClearPrestoredFreezeFrame, queue-length=1
          operation=ResetEventDebounceStatus, queue-length=1
          operation=SetEventDisabled, queue-length=1
      Event_DemEventParameter_ECU3_DTC06: provided-interface=DiagnosticMonitor
        provided-com-specs:
          operation=SetEventStatus, queue-length=1
          operation=SetEventStatusWithEnvdata, queue-length=1
          operation=ResetEventStatus, queue-length=1
          operation=PrestoreFreezeFrame, queue-length=1
          operation=ClearPrestoredFreezeFrame, queue-length=1
          operation=ResetEventDebounceStatus, queue-length=1
          operation=SetEventDisabled, queue-length=1
      Event_DemEventParameter_ECU3_DTC07: provided-interface=DiagnosticMonitor
        provided-com-specs:
          operation=SetEventStatus, queue-length=1
          operation=SetEventStatusWithEnvdata, queue-length=1
          operation=ResetEventStatus, queue-length=1
          operation=PrestoreFreezeFrame, queue-length=1
          operation=ClearPrestoredFreezeFrame, queue-length=1
          operation=ResetEventDebounceStatus, queue-length=1
          operation=SetEventDisabled, queue-length=1
      Event_DemEventParameter_ECU3_DTC08: provided-interface=DiagnosticMonitor
        provided-com-specs:
          operation=SetEventStatus, queue-length=1
          operation=SetEventStatusWithEnvdata, queue-length=1
          operation=ResetEventStatus, queue-length=1
          operation=PrestoreFreezeFrame, queue-length=1
          operation=ClearPrestoredFreezeFrame, queue-length=1
          operation=ResetEventDebounceStatus, queue-length=1
          operation=SetEventDisabled, queue-length=1
      Event_DemEventParameter_ECU3_DTC09: provided-interface=DiagnosticMonitor
        provided-com-specs:
          operation=SetEventStatus, queue-length=1
          operation=SetEventStatusWithEnvdata, queue-length=1
          operation=ResetEventStatus, queue-length=1
          operation=PrestoreFreezeFrame, queue-length=1
          operation=ClearPrestoredFreezeFrame, queue-length=1
          operation=ResetEventDebounceStatus, queue-length=1
          operation=SetEventDisabled, queue-length=1
      Event_DemEventParameter_ECU3_DTC10: provided-interface=DiagnosticMonitor
        provided-com-specs:
          operation=SetEventStatus, queue-length=1
          operation=SetEventStatusWithEnvdata, queue-length=1
          operation=ResetEventStatus, queue-length=1
          operation=PrestoreFreezeFrame, queue-length=1
          operation=ClearPrestoredFreezeFrame, queue-length=1
          operation=ResetEventDebounceStatus, queue-length=1
          operation=SetEventDisabled, queue-length=1
      Event_DemEventParameter_ECU3_DTC11: provided-interface=DiagnosticMonitor
        provided-com-specs:
          operation=SetEventStatus, queue-length=1
          operation=SetEventStatusWithEnvdata, queue-length=1
          operation=ResetEventStatus, queue-length=1
          operation=PrestoreFreezeFrame, queue-length=1
          operation=ClearPrestoredFreezeFrame, queue-length=1
          operation=ResetEventDebounceStatus, queue-length=1
          operation=SetEventDisabled, queue-length=1
      Event_DemEventParameter_ECU3_DTC12: provided-interface=DiagnosticMonitor
        provided-com-specs:
          operation=SetEventStatus, queue-length=1
          operation=SetEventStatusWithEnvdata, queue-length=1
          operation=ResetEventStatus, queue-length=1
          operation=PrestoreFreezeFrame, queue-length=1
          operation=ClearPrestoredFreezeFrame, queue-length=1
          operation=ResetEventDebounceStatus, queue-length=1
          operation=SetEventDisabled, queue-length=1
      Event_DemEventParameter_ECU3_DTC13: provided-interface=DiagnosticMonitor
        provided-com-specs:
          operation=SetEventStatus, queue-length=1
          operation=SetEventStatusWithEnvdata, queue-length=1
          operation=ResetEventStatus, queue-length=1
          operation=PrestoreFreezeFrame, queue-length=1
          operation=ClearPrestoredFreezeFrame, queue-length=1
          operation=ResetEventDebounceStatus, queue-length=1
          operation=SetEventDisabled, queue-length=1
      Event_DemEventParameter_ECU3_DTC14: provided-interface=DiagnosticMonitor
        provided-com-specs:
          operation=SetEventStatus, queue-length=1
          operation=SetEventStatusWithEnvdata, queue-length=1
          operation=ResetEventStatus, queue-length=1
          operation=PrestoreFreezeFrame, queue-length=1
          operation=ClearPrestoredFreezeFrame, queue-length=1
          operation=ResetEventDebounceStatus, queue-length=1
          operation=SetEventDisabled, queue-length=1
      Event_DemEventParameter_ECU3_DTC15: provided-interface=DiagnosticMonitor
        provided-com-specs:
          operation=SetEventStatus, queue-length=1
          operation=SetEventStatusWithEnvdata, queue-length=1
          operation=ResetEventStatus, queue-length=1
          operation=PrestoreFreezeFrame, queue-length=1
          operation=ClearPrestoredFreezeFrame, queue-length=1
          operation=ResetEventDebounceStatus, queue-length=1
          operation=SetEventDisabled, queue-length=1
      Event_DemEventParameter_ECU3_DTC16: provided-interface=DiagnosticMonitor
        provided-com-specs:
          operation=SetEventStatus, queue-length=1
          operation=SetEventStatusWithEnvdata, queue-length=1
          operation=ResetEventStatus, queue-length=1
          operation=PrestoreFreezeFrame, queue-length=1
          operation=ClearPrestoredFreezeFrame, queue-length=1
          operation=ResetEventDebounceStatus, queue-length=1
          operation=SetEventDisabled, queue-length=1
      Event_DemEventParameter_ECU3_DTC17: provided-interface=DiagnosticMonitor
        provided-com-specs:
          operation=SetEventStatus, queue-length=1
          operation=SetEventStatusWithEnvdata, queue-length=1
          operation=ResetEventStatus, queue-length=1
          operation=PrestoreFreezeFrame, queue-length=1
          operation=ClearPrestoredFreezeFrame, queue-length=1
          operation=ResetEventDebounceStatus, queue-length=1
          operation=SetEventDisabled, queue-length=1
      Event_DemEventParameter_ECU3_DTC18: provided-interface=DiagnosticMonitor
        provided-com-specs:
          operation=SetEventStatus, queue-length=1
          operation=SetEventStatusWithEnvdata, queue-length=1
          operation=ResetEventStatus, queue-length=1
          operation=PrestoreFreezeFrame, queue-length=1
          operation=ClearPrestoredFreezeFrame, queue-length=1
          operation=ResetEventDebounceStatus, queue-length=1
          operation=SetEventDisabled, queue-length=1
      Event_DemEventParameter_ECU3_DTC19: provided-interface=DiagnosticMonitor
        provided-com-specs:
          operation=SetEventStatus, queue-length=1
          operation=SetEventStatusWithEnvdata, queue-length=1
          operation=ResetEventStatus, queue-length=1
          operation=PrestoreFreezeFrame, queue-length=1
          operation=ClearPrestoredFreezeFrame, queue-length=1
          operation=ResetEventDebounceStatus, queue-length=1
          operation=SetEventDisabled, queue-length=1
      Event_DemEventParameter_ECU3_DTC20: provided-interface=DiagnosticMonitor
        provided-com-specs:
          operation=SetEventStatus, queue-length=1
          operation=SetEventStatusWithEnvdata, queue-length=1
          operation=ResetEventStatus, queue-length=1
          operation=PrestoreFreezeFrame, queue-length=1
          operation=ClearPrestoredFreezeFrame, queue-length=1
          operation=ResetEventDebounceStatus, queue-length=1
          operation=SetEventDisabled, queue-length=1
      Event_DemEventParameter_ECU3_DTC21: provided-interface=DiagnosticMonitor
        provided-com-specs:
          operation=SetEventStatus, queue-length=1
          operation=SetEventStatusWithEnvdata, queue-length=1
          operation=ResetEventStatus, queue-length=1
          operation=PrestoreFreezeFrame, queue-length=1
          operation=ClearPrestoredFreezeFrame, queue-length=1
          operation=ResetEventDebounceStatus, queue-length=1
          operation=SetEventDisabled, queue-length=1
      Event_DemEventParameter_ECU3_DTC22: provided-interface=DiagnosticMonitor
        provided-com-specs:
          operation=SetEventStatus, queue-length=1
          operation=SetEventStatusWithEnvdata, queue-length=1
          operation=ResetEventStatus, queue-length=1
          operation=PrestoreFreezeFrame, queue-length=1
          operation=ClearPrestoredFreezeFrame, queue-length=1
          operation=ResetEventDebounceStatus, queue-length=1
          operation=SetEventDisabled, queue-length=1
      Event_DemEventParameter_ECU3_DTC23: provided-interface=DiagnosticMonitor
        provided-com-specs:
          operation=SetEventStatus, queue-length=1
          operation=SetEventStatusWithEnvdata, queue-length=1
          operation=ResetEventStatus, queue-length=1
          operation=PrestoreFreezeFrame, queue-length=1
          operation=ClearPrestoredFreezeFrame, queue-length=1
          operation=ResetEventDebounceStatus, queue-length=1
          operation=SetEventDisabled, queue-length=1
      Event_DemEventParameter_ECU3_DTC24: provided-interface=DiagnosticMonitor
        provided-com-specs:
          operation=SetEventStatus, queue-length=1
          operation=SetEventStatusWithEnvdata, queue-length=1
          operation=ResetEventStatus, queue-length=1
          operation=PrestoreFreezeFrame, queue-length=1
          operation=ClearPrestoredFreezeFrame, queue-length=1
          operation=ResetEventDebounceStatus, queue-length=1
          operation=SetEventDisabled, queue-length=1
      Event_DemEventParameter_ECU3_DTC25: provided-interface=DiagnosticMonitor
        provided-com-specs:
          operation=SetEventStatus, queue-length=1
          operation=SetEventStatusWithEnvdata, queue-length=1
          operation=ResetEventStatus, queue-length=1
          operation=PrestoreFreezeFrame, queue-length=1
          operation=ClearPrestoredFreezeFrame, queue-length=1
          operation=ResetEventDebounceStatus, queue-length=1
          operation=SetEventDisabled, queue-length=1
      Event_DemEventParameter_ECU3_DTC26: provided-interface=DiagnosticMonitor
        provided-com-specs:
          operation=SetEventStatus, queue-length=1
          operation=SetEventStatusWithEnvdata, queue-length=1
          operation=ResetEventStatus, queue-length=1
          operation=PrestoreFreezeFrame, queue-length=1
          operation=ClearPrestoredFreezeFrame, queue-length=1
          operation=ResetEventDebounceStatus, queue-length=1
          operation=SetEventDisabled, queue-length=1
      Event_DemEventParameter_ECU3_DTC27: provided-interface=DiagnosticMonitor
        provided-com-specs:
          operation=SetEventStatus, queue-length=1
          operation=SetEventStatusWithEnvdata, queue-length=1
          operation=ResetEventStatus, queue-length=1
          operation=PrestoreFreezeFrame, queue-length=1
          operation=ClearPrestoredFreezeFrame, queue-length=1
          operation=ResetEventDebounceStatus, queue-length=1
          operation=SetEventDisabled, queue-length=1
      Event_DemEventParameter_ECU3_DTC28: provided-interface=DiagnosticMonitor
        provided-com-specs:
          operation=SetEventStatus, queue-length=1
          operation=SetEventStatusWithEnvdata, queue-length=1
          operation=ResetEventStatus, queue-length=1
          operation=PrestoreFreezeFrame, queue-length=1
          operation=ClearPrestoredFreezeFrame, queue-length=1
          operation=ResetEventDebounceStatus, queue-length=1
          operation=SetEventDisabled, queue-length=1
      Event_DemEventParameter_ECU3_DTC29: provided-interface=DiagnosticMonitor
        provided-com-specs:
          operation=SetEventStatus, queue-length=1
          operation=SetEventStatusWithEnvdata, queue-length=1
          operation=ResetEventStatus, queue-length=1
          operation=PrestoreFreezeFrame, queue-length=1
          operation=ClearPrestoredFreezeFrame, queue-length=1
          operation=ResetEventDebounceStatus, queue-length=1
          operation=SetEventDisabled, queue-length=1
      Event_DemEventParameter_ECU3_DTC30: provided-interface=DiagnosticMonitor
        provided-com-specs:
          operation=SetEventStatus, queue-length=1
          operation=SetEventStatusWithEnvdata, queue-length=1
          operation=ResetEventStatus, queue-length=1
          operation=PrestoreFreezeFrame, queue-length=1
          operation=ClearPrestoredFreezeFrame, queue-length=1
          operation=ResetEventDebounceStatus, queue-length=1
          operation=SetEventDisabled, queue-length=1
      Event_DemEventParameter_ECU3_DTC31: provided-interface=DiagnosticMonitor
        provided-com-specs:
          operation=SetEventStatus, queue-length=1
          operation=SetEventStatusWithEnvdata, queue-length=1
          operation=ResetEventStatus, queue-length=1
          operation=PrestoreFreezeFrame, queue-length=1
          operation=ClearPrestoredFreezeFrame, queue-length=1
          operation=ResetEventDebounceStatus, queue-length=1
          operation=SetEventDisabled, queue-length=1
      Event_DemEventParameter_ECU3_DTC32: provided-interface=DiagnosticMonitor
        provided-com-specs:
          operation=SetEventStatus, queue-length=1
          operation=SetEventStatusWithEnvdata, queue-length=1
          operation=ResetEventStatus, queue-length=1
          operation=PrestoreFreezeFrame, queue-length=1
          operation=ClearPrestoredFreezeFrame, queue-length=1
          operation=ResetEventDebounceStatus, queue-length=1
          operation=SetEventDisabled, queue-length=1
      Event_DemEventParameter_ECU3_DTC33: provided-interface=DiagnosticMonitor
        provided-com-specs:
          operation=SetEventStatus, queue-length=1
          operation=SetEventStatusWithEnvdata, queue-length=1
          operation=ResetEventStatus, queue-length=1
          operation=PrestoreFreezeFrame, queue-length=1
          operation=ClearPrestoredFreezeFrame, queue-length=1
          operation=ResetEventDebounceStatus, queue-length=1
          operation=SetEventDisabled, queue-length=1
      Event_DemEventParameter_ECU3_DTC34: provided-interface=DiagnosticMonitor
        provided-com-specs:
          operation=SetEventStatus, queue-length=1
          operation=SetEventStatusWithEnvdata, queue-length=1
          operation=ResetEventStatus, queue-length=1
          operation=PrestoreFreezeFrame, queue-length=1
          operation=ClearPrestoredFreezeFrame, queue-length=1
          operation=ResetEventDebounceStatus, queue-length=1
          operation=SetEventDisabled, queue-length=1
      Event_DemEventParameter_ECU3_DTC35: provided-interface=DiagnosticMonitor
        provided-com-specs:
          operation=SetEventStatus, queue-length=1
          operation=SetEventStatusWithEnvdata, queue-length=1
          operation=ResetEventStatus, queue-length=1
          operation=PrestoreFreezeFrame, queue-length=1
          operation=ClearPrestoredFreezeFrame, queue-length=1
          operation=ResetEventDebounceStatus, queue-length=1
          operation=SetEventDisabled, queue-length=1
      Event_DemEventParameter_ECU3_DTC36: provided-interface=DiagnosticMonitor
        provided-com-specs:
          operation=SetEventStatus, queue-length=1
          operation=SetEventStatusWithEnvdata, queue-length=1
          operation=ResetEventStatus, queue-length=1
          operation=PrestoreFreezeFrame, queue-length=1
          operation=ClearPrestoredFreezeFrame, queue-length=1
          operation=ResetEventDebounceStatus, queue-length=1
          operation=SetEventDisabled, queue-length=1
      Event_DemEventParameter_ECU3_DTC37: provided-interface=DiagnosticMonitor
        provided-com-specs:
          operation=SetEventStatus, queue-length=1
          operation=SetEventStatusWithEnvdata, queue-length=1
          operation=ResetEventStatus, queue-length=1
          operation=PrestoreFreezeFrame, queue-length=1
          operation=ClearPrestoredFreezeFrame, queue-length=1
          operation=ResetEventDebounceStatus, queue-length=1
          operation=SetEventDisabled, queue-length=1
      Event_DemEventParameter_ECU3_DTC38: provided-interface=DiagnosticMonitor
        provided-com-specs:
          operation=SetEventStatus, queue-length=1
          operation=SetEventStatusWithEnvdata, queue-length=1
          operation=ResetEventStatus, queue-length=1
          operation=PrestoreFreezeFrame, queue-length=1
          operation=ClearPrestoredFreezeFrame, queue-length=1
          operation=ResetEventDebounceStatus, queue-length=1
          operation=SetEventDisabled, queue-length=1
      Event_DemEventParameter_ECU3_DTC39: provided-interface=DiagnosticMonitor
        provided-com-specs:
          operation=SetEventStatus, queue-length=1
          operation=SetEventStatusWithEnvdata, queue-length=1
          operation=ResetEventStatus, queue-length=1
          operation=PrestoreFreezeFrame, queue-length=1
          operation=ClearPrestoredFreezeFrame, queue-length=1
          operation=ResetEventDebounceStatus, queue-length=1
          operation=SetEventDisabled, queue-length=1
      Event_DemEventParameter_ECU3_DTC40: provided-interface=DiagnosticMonitor
        provided-com-specs:
          operation=SetEventStatus, queue-length=1
          operation=SetEventStatusWithEnvdata, queue-length=1
          operation=ResetEventStatus, queue-length=1
          operation=PrestoreFreezeFrame, queue-length=1
          operation=ClearPrestoredFreezeFrame, queue-length=1
          operation=ResetEventDebounceStatus, queue-length=1
          operation=SetEventDisabled, queue-length=1
      Event_DemEventParameter_ECU3_DTC41: provided-interface=DiagnosticMonitor
        provided-com-specs:
          operation=SetEventStatus, queue-length=1
          operation=SetEventStatusWithEnvdata, queue-length=1
          operation=ResetEventStatus, queue-length=1
          operation=PrestoreFreezeFrame, queue-length=1
          operation=ClearPrestoredFreezeFrame, queue-length=1
          operation=ResetEventDebounceStatus, queue-length=1
          operation=SetEventDisabled, queue-length=1
      Event_DemEventParameter_ECU3_DTC42: provided-interface=DiagnosticMonitor
        provided-com-specs:
          operation=SetEventStatus, queue-length=1
          operation=SetEventStatusWithEnvdata, queue-length=1
          operation=ResetEventStatus, queue-length=1
          operation=PrestoreFreezeFrame, queue-length=1
          operation=ClearPrestoredFreezeFrame, queue-length=1
          operation=ResetEventDebounceStatus, queue-length=1
          operation=SetEventDisabled, queue-length=1
      Event_DemEventParameter_ECU3_DTC43: provided-interface=DiagnosticMonitor
        provided-com-specs:
          operation=SetEventStatus, queue-length=1
          operation=SetEventStatusWithEnvdata, queue-length=1
          operation=ResetEventStatus, queue-length=1
          operation=PrestoreFreezeFrame, queue-length=1
          operation=ClearPrestoredFreezeFrame, queue-length=1
          operation=ResetEventDebounceStatus, queue-length=1
          operation=SetEventDisabled, queue-length=1
      Event_DemEventParameter_ECU3_DTC44: provided-interface=DiagnosticMonitor
        provided-com-specs:
          operation=SetEventStatus, queue-length=1
          operation=SetEventStatusWithEnvdata, queue-length=1
          operation=ResetEventStatus, queue-length=1
          operation=PrestoreFreezeFrame, queue-length=1
          operation=ClearPrestoredFreezeFrame, queue-length=1
          operation=ResetEventDebounceStatus, queue-length=1
          operation=SetEventDisabled, queue-length=1
      Event_DemEventParameter_ECU3_DTC45: provided-interface=DiagnosticMonitor
        provided-com-specs:
          operation=SetEventStatus, queue-length=1
          operation=SetEventStatusWithEnvdata, queue-length=1
          operation=ResetEventStatus, queue-length=1
          operation=PrestoreFreezeFrame, queue-length=1
          operation=ClearPrestoredFreezeFrame, queue-length=1
          operation=ResetEventDebounceStatus, queue-length=1
          operation=SetEventDisabled, queue-length=1
      Event_DemEventParameter_ECU3_DTC46: provided-interface=DiagnosticMonitor
        provided-com-specs:
          operation=SetEventStatus, queue-length=1
          operation=SetEventStatusWithEnvdata, queue-length=1
          operation=ResetEventStatus, queue-length=1
          operation=PrestoreFreezeFrame, queue-length=1
          operation=ClearPrestoredFreezeFrame, queue-length=1
          operation=ResetEventDebounceStatus, queue-length=1
          operation=SetEventDisabled, queue-length=1
      Event_DemEventParameter_ECU3_DTC47: provided-interface=DiagnosticMonitor
        provided-com-specs:
          operation=SetEventStatus, queue-length=1
          operation=SetEventStatusWithEnvdata, queue-length=1
          operation=ResetEventStatus, queue-length=1
          operation=PrestoreFreezeFrame, queue-length=1
          operation=ClearPrestoredFreezeFrame, queue-length=1
          operation=ResetEventDebounceStatus, queue-length=1
          operation=SetEventDisabled, queue-length=1
      Event_DemEventParameter_ECU3_DTC48: provided-interface=DiagnosticMonitor
        provided-com-specs:
          operation=SetEventStatus, queue-length=1
          operation=SetEventStatusWithEnvdata, queue-length=1
          operation=ResetEventStatus, queue-length=1
          operation=PrestoreFreezeFrame, queue-length=1
          operation=ClearPrestoredFreezeFrame, queue-length=1
          operation=ResetEventDebounceStatus, queue-length=1
          operation=SetEventDisabled, queue-length=1
      Event_DemEventParameter_ECU3_DTC49: provided-interface=DiagnosticMonitor
        provided-com-specs:
          operation=SetEventStatus, queue-length=1
          operation=SetEventStatusWithEnvdata, queue-length=1
          operation=ResetEventStatus, queue-length=1
          operation=PrestoreFreezeFrame, queue-length=1
          operation=ClearPrestoredFreezeFrame, queue-length=1
          operation=ResetEventDebounceStatus, queue-length=1
          operation=SetEventDisabled, queue-length=1
      Event_DemEventParameter_ECU3_DTC50: provided-interface=DiagnosticMonitor
        provided-com-specs:
          operation=SetEventStatus, queue-length=1
          operation=SetEventStatusWithEnvdata, queue-length=1
          operation=ResetEventStatus, queue-length=1
          operation=PrestoreFreezeFrame, queue-length=1
          operation=ClearPrestoredFreezeFrame, queue-length=1
          operation=ResetEventDebounceStatus, queue-length=1
          operation=SetEventDisabled, queue-length=1
      Event_DemEventParameter_ECU3_DTC51: provided-interface=DiagnosticMonitor
        provided-com-specs:
          operation=SetEventStatus, queue-length=1
          operation=SetEventStatusWithEnvdata, queue-length=1
          operation=ResetEventStatus, queue-length=1
          operation=PrestoreFreezeFrame, queue-length=1
          operation=ClearPrestoredFreezeFrame, queue-length=1
          operation=ResetEventDebounceStatus, queue-length=1
          operation=SetEventDisabled, queue-length=1
      Event_DemEventParameter_ECU3_DTC52: provided-interface=DiagnosticMonitor
        provided-com-specs:
          operation=SetEventStatus, queue-length=1
          operation=SetEventStatusWithEnvdata, queue-length=1
          operation=ResetEventStatus, queue-length=1
          operation=PrestoreFreezeFrame, queue-length=1
          operation=ClearPrestoredFreezeFrame, queue-length=1
          operation=ResetEventDebounceStatus, queue-length=1
          operation=SetEventDisabled, queue-length=1
      Event_DemEventParameter_ECU3_DTC53: provided-interface=DiagnosticMonitor
        provided-com-specs:
          operation=SetEventStatus, queue-length=1
          operation=SetEventStatusWithEnvdata, queue-length=1
          operation=ResetEventStatus, queue-length=1
          operation=PrestoreFreezeFrame, queue-length=1
          operation=ClearPrestoredFreezeFrame, queue-length=1
          operation=ResetEventDebounceStatus, queue-length=1
          operation=SetEventDisabled, queue-length=1
      Event_DemEventParameter_ECU3_DTC54: provided-interface=DiagnosticMonitor
        provided-com-specs:
          operation=SetEventStatus, queue-length=1
          operation=SetEventStatusWithEnvdata, queue-length=1
          operation=ResetEventStatus, queue-length=1
          operation=PrestoreFreezeFrame, queue-length=1
          operation=ClearPrestoredFreezeFrame, queue-length=1
          operation=ResetEventDebounceStatus, queue-length=1
          operation=SetEventDisabled, queue-length=1
      Event_DemEventParameter_ECU3_DTC55: provided-interface=DiagnosticMonitor
        provided-com-specs:
          operation=SetEventStatus, queue-length=1
          operation=SetEventStatusWithEnvdata, queue-length=1
          operation=ResetEventStatus, queue-length=1
          operation=PrestoreFreezeFrame, queue-length=1
          operation=ClearPrestoredFreezeFrame, queue-length=1
          operation=ResetEventDebounceStatus, queue-length=1
          operation=SetEventDisabled, queue-length=1
      Event_DemEventParameter_ECU3_DTC56: provided-interface=DiagnosticMonitor
        provided-com-specs:
          operation=SetEventStatus, queue-length=1
          operation=SetEventStatusWithEnvdata, queue-length=1
          operation=ResetEventStatus, queue-length=1
          operation=PrestoreFreezeFrame, queue-length=1
          operation=ClearPrestoredFreezeFrame, queue-length=1
          operation=ResetEventDebounceStatus, queue-length=1
          operation=SetEventDisabled, queue-length=1
      Event_DemEventParameter_ECU3_DTC57: provided-interface=DiagnosticMonitor
        provided-com-specs:
          operation=SetEventStatus, queue-length=1
          operation=SetEventStatusWithEnvdata, queue-length=1
          operation=ResetEventStatus, queue-length=1
          operation=PrestoreFreezeFrame, queue-length=1
          operation=ClearPrestoredFreezeFrame, queue-length=1
          operation=ResetEventDebounceStatus, queue-length=1
          operation=SetEventDisabled, queue-length=1
      Event_DemEventParameter_ECU3_DTC58: provided-interface=DiagnosticMonitor
        provided-com-specs:
          operation=SetEventStatus, queue-length=1
          operation=SetEventStatusWithEnvdata, queue-length=1
          operation=ResetEventStatus, queue-length=1
          operation=PrestoreFreezeFrame, queue-length=1
          operation=ClearPrestoredFreezeFrame, queue-length=1
          operation=ResetEventDebounceStatus, queue-length=1
          operation=SetEventDisabled, queue-length=1
      Event_DemEventParameter_ECU3_DTC59: provided-interface=DiagnosticMonitor
        provided-com-specs:
          operation=SetEventStatus, queue-length=1
          operation=SetEventStatusWithEnvdata, queue-length=1
          operation=ResetEventStatus, queue-length=1
          operation=PrestoreFreezeFrame, queue-length=1
          operation=ClearPrestoredFreezeFrame, queue-length=1
          operation=ResetEventDebounceStatus, queue-length=1
          operation=SetEventDisabled, queue-length=1
      Event_DemEventParameter_ECU3_DTC60: provided-interface=DiagnosticMonitor
        provided-com-specs:
          operation=SetEventStatus, queue-length=1
          operation=SetEventStatusWithEnvdata, queue-length=1
          operation=ResetEventStatus, queue-length=1
          operation=PrestoreFreezeFrame, queue-length=1
          operation=ClearPrestoredFreezeFrame, queue-length=1
          operation=ResetEventDebounceStatus, queue-length=1
          operation=SetEventDisabled, queue-length=1
      Event_DemEventParameter_ECU3_DTC61: provided-interface=DiagnosticMonitor
        provided-com-specs:
          operation=SetEventStatus, queue-length=1
          operation=SetEventStatusWithEnvdata, queue-length=1
          operation=ResetEventStatus, queue-length=1
          operation=PrestoreFreezeFrame, queue-length=1
          operation=ClearPrestoredFreezeFrame, queue-length=1
          operation=ResetEventDebounceStatus, queue-length=1
          operation=SetEventDisabled, queue-length=1
      Event_DemEventParameter_ECU3_DTC62: provided-interface=DiagnosticMonitor
        provided-com-specs:
          operation=SetEventStatus, queue-length=1
          operation=SetEventStatusWithEnvdata, queue-length=1
          operation=ResetEventStatus, queue-length=1
          operation=PrestoreFreezeFrame, queue-length=1
          operation=ClearPrestoredFreezeFrame, queue-length=1
          operation=ResetEventDebounceStatus, queue-length=1
          operation=SetEventDisabled, queue-length=1
      Event_DemEventParameter_ECU3_DTC63: provided-interface=DiagnosticMonitor
        provided-com-specs:
          operation=SetEventStatus, queue-length=1
          operation=SetEventStatusWithEnvdata, queue-length=1
          operation=ResetEventStatus, queue-length=1
          operation=PrestoreFreezeFrame, queue-length=1
          operation=ClearPrestoredFreezeFrame, queue-length=1
          operation=ResetEventDebounceStatus, queue-length=1
          operation=SetEventDisabled, queue-length=1
      Event_DemEventParameter_ECU3_DTC64: provided-interface=DiagnosticMonitor
        provided-com-specs:
          operation=SetEventStatus, queue-length=1
          operation=SetEventStatusWithEnvdata, queue-length=1
          operation=ResetEventStatus, queue-length=1
          operation=PrestoreFreezeFrame, queue-length=1
          operation=ClearPrestoredFreezeFrame, queue-length=1
          operation=ResetEventDebounceStatus, queue-length=1
          operation=SetEventDisabled, queue-length=1
      Event_DemEventParameter_ECU3_DTC65: provided-interface=DiagnosticMonitor
        provided-com-specs:
          operation=SetEventStatus, queue-length=1
          operation=SetEventStatusWithEnvdata, queue-length=1
          operation=ResetEventStatus, queue-length=1
          operation=PrestoreFreezeFrame, queue-length=1
          operation=ClearPrestoredFreezeFrame, queue-length=1
          operation=ResetEventDebounceStatus, queue-length=1
          operation=SetEventDisabled, queue-length=1
      Event_DemEventParameter_ECU3_DTC66: provided-interface=DiagnosticMonitor
        provided-com-specs:
          operation=SetEventStatus, queue-length=1
          operation=SetEventStatusWithEnvdata, queue-length=1
          operation=ResetEventStatus, queue-length=1
          operation=PrestoreFreezeFrame, queue-length=1
          operation=ClearPrestoredFreezeFrame, queue-length=1
          operation=ResetEventDebounceStatus, queue-length=1
          operation=SetEventDisabled, queue-length=1
      Event_DemEventParameter_ECU3_DTC67: provided-interface=DiagnosticMonitor
        provided-com-specs:
          operation=SetEventStatus, queue-length=1
          operation=SetEventStatusWithEnvdata, queue-length=1
          operation=ResetEventStatus, queue-length=1
          operation=PrestoreFreezeFrame, queue-length=1
          operation=ClearPrestoredFreezeFrame, queue-length=1
          operation=ResetEventDebounceStatus, queue-length=1
          operation=SetEventDisabled, queue-length=1
      Event_DemEventParameter_ECU3_DTC68: provided-interface=DiagnosticMonitor
        provided-com-specs:
          operation=SetEventStatus, queue-length=1
          operation=SetEventStatusWithEnvdata, queue-length=1
          operation=ResetEventStatus, queue-length=1
          operation=PrestoreFreezeFrame, queue-length=1
          operation=ClearPrestoredFreezeFrame, queue-length=1
          operation=ResetEventDebounceStatus, queue-length=1
          operation=SetEventDisabled, queue-length=1
      Event_DemEventParameter_ECU3_DTC69: provided-interface=DiagnosticMonitor
        provided-com-specs:
          operation=SetEventStatus, queue-length=1
          operation=SetEventStatusWithEnvdata, queue-length=1
          operation=ResetEventStatus, queue-length=1
          operation=PrestoreFreezeFrame, queue-length=1
          operation=ClearPrestoredFreezeFrame, queue-length=1
          operation=ResetEventDebounceStatus, queue-length=1
          operation=SetEventDisabled, queue-length=1
      Event_DemEventParameter_ECU3_DTC70: provided-interface=DiagnosticMonitor
        provided-com-specs:
          operation=SetEventStatus, queue-length=1
          operation=SetEventStatusWithEnvdata, queue-length=1
          operation=ResetEventStatus, queue-length=1
          operation=PrestoreFreezeFrame, queue-length=1
          operation=ClearPrestoredFreezeFrame, queue-length=1
          operation=ResetEventDebounceStatus, queue-length=1
          operation=SetEventDisabled, queue-length=1
      Event_DemEventParameter_ECU3_DTC71: provided-interface=DiagnosticMonitor
        provided-com-specs:
          operation=SetEventStatus, queue-length=1
          operation=SetEventStatusWithEnvdata, queue-length=1
          operation=ResetEventStatus, queue-length=1
          operation=PrestoreFreezeFrame, queue-length=1
          operation=ClearPrestoredFreezeFrame, queue-length=1
          operation=ResetEventDebounceStatus, queue-length=1
          operation=SetEventDisabled, queue-length=1
      Event_DemEventParameter_ECU3_DTC72: provided-interface=DiagnosticMonitor
        provided-com-specs:
          operation=SetEventStatus, queue-length=1
          operation=SetEventStatusWithEnvdata, queue-length=1
          operation=ResetEventStatus, queue-length=1
          operation=PrestoreFreezeFrame, queue-length=1
          operation=ClearPrestoredFreezeFrame, queue-length=1
          operation=ResetEventDebounceStatus, queue-length=1
          operation=SetEventDisabled, queue-length=1
      Event_DemEventParameter_ECU3_DTC73: provided-interface=DiagnosticMonitor
        provided-com-specs:
          operation=SetEventStatus, queue-length=1
          operation=SetEventStatusWithEnvdata, queue-length=1
          operation=ResetEventStatus, queue-length=1
          operation=PrestoreFreezeFrame, queue-length=1
          operation=ClearPrestoredFreezeFrame, queue-length=1
          operation=ResetEventDebounceStatus, queue-length=1
          operation=SetEventDisabled, queue-length=1
      Event_DemEventParameter_ECU3_DTC74: provided-interface=DiagnosticMonitor
        provided-com-specs:
          operation=SetEventStatus, queue-length=1
          operation=SetEventStatusWithEnvdata, queue-length=1
          operation=ResetEventStatus, queue-length=1
          operation=PrestoreFreezeFrame, queue-length=1
          operation=ClearPrestoredFreezeFrame, queue-length=1
          operation=ResetEventDebounceStatus, queue-length=1
          operation=SetEventDisabled, queue-length=1
      Event_DemEventParameter_ECU3_DTC75: provided-interface=DiagnosticMonitor
        provided-com-specs:
          operation=SetEventStatus, queue-length=1
          operation=SetEventStatusWithEnvdata, queue-length=1
          operation=ResetEventStatus, queue-length=1
          operation=PrestoreFreezeFrame, queue-length=1
          operation=ClearPrestoredFreezeFrame, queue-length=1
          operation=ResetEventDebounceStatus, queue-length=1
          operation=SetEventDisabled, queue-length=1
      Event_DemEventParameter_ECU3_DTC76: provided-interface=DiagnosticMonitor
        provided-com-specs:
          operation=SetEventStatus, queue-length=1
          operation=SetEventStatusWithEnvdata, queue-length=1
          operation=ResetEventStatus, queue-length=1
          operation=PrestoreFreezeFrame, queue-length=1
          operation=ClearPrestoredFreezeFrame, queue-length=1
          operation=ResetEventDebounceStatus, queue-length=1
          operation=SetEventDisabled, queue-length=1
      Event_DemEventParameter_ECU3_DTC77: provided-interface=DiagnosticMonitor
        provided-com-specs:
          operation=SetEventStatus, queue-length=1
          operation=SetEventStatusWithEnvdata, queue-length=1
          operation=ResetEventStatus, queue-length=1
          operation=PrestoreFreezeFrame, queue-length=1
          operation=ClearPrestoredFreezeFrame, queue-length=1
          operation=ResetEventDebounceStatus, queue-length=1
          operation=SetEventDisabled, queue-length=1
      Event_DemEventParameter_ECU3_DTC78: provided-interface=DiagnosticMonitor
        provided-com-specs:
          operation=SetEventStatus, queue-length=1
          operation=SetEventStatusWithEnvdata, queue-length=1
          operation=ResetEventStatus, queue-length=1
          operation=PrestoreFreezeFrame, queue-length=1
          operation=ClearPrestoredFreezeFrame, queue-length=1
          operation=ResetEventDebounceStatus, queue-length=1
          operation=SetEventDisabled, queue-length=1
      Event_DemEventParameter_ECU3_DTC79: provided-interface=DiagnosticMonitor
        provided-com-specs:
          operation=SetEventStatus, queue-length=1
          operation=SetEventStatusWithEnvdata, queue-length=1
          operation=ResetEventStatus, queue-length=1
          operation=PrestoreFreezeFrame, queue-length=1
          operation=ClearPrestoredFreezeFrame, queue-length=1
          operation=ResetEventDebounceStatus, queue-length=1
          operation=SetEventDisabled, queue-length=1
      Event_DemEventParameter_ECU3_DTC80: provided-interface=DiagnosticMonitor
        provided-com-specs:
          operation=SetEventStatus, queue-length=1
          operation=SetEventStatusWithEnvdata, queue-length=1
          operation=ResetEventStatus, queue-length=1
          operation=PrestoreFreezeFrame, queue-length=1
          operation=ClearPrestoredFreezeFrame, queue-length=1
          operation=ResetEventDebounceStatus, queue-length=1
          operation=SetEventDisabled, queue-length=1
      Event_DemEventParameter_ECU3_DTC81: provided-interface=DiagnosticMonitor
        provided-com-specs:
          operation=SetEventStatus, queue-length=1
          operation=SetEventStatusWithEnvdata, queue-length=1
          operation=ResetEventStatus, queue-length=1
          operation=PrestoreFreezeFrame, queue-length=1
          operation=ClearPrestoredFreezeFrame, queue-length=1
          operation=ResetEventDebounceStatus, queue-length=1
          operation=SetEventDisabled, queue-length=1
      Event_DemEventParameter_ECU3_DTC82: provided-interface=DiagnosticMonitor
        provided-com-specs:
          operation=SetEventStatus, queue-length=1
          operation=SetEventStatusWithEnvdata, queue-length=1
          operation=ResetEventStatus, queue-length=1
          operation=PrestoreFreezeFrame, queue-length=1
          operation=ClearPrestoredFreezeFrame, queue-length=1
          operation=ResetEventDebounceStatus, queue-length=1
          operation=SetEventDisabled, queue-length=1
      Event_DemEventParameter_ECU3_DTC83: provided-interface=DiagnosticMonitor
        provided-com-specs:
          operation=SetEventStatus, queue-length=1
          operation=SetEventStatusWithEnvdata, queue-length=1
          operation=ResetEventStatus, queue-length=1
          operation=PrestoreFreezeFrame, queue-length=1
          operation=ClearPrestoredFreezeFrame, queue-length=1
          operation=ResetEventDebounceStatus, queue-length=1
          operation=SetEventDisabled, queue-length=1
      Event_DemEventParameter_ECU3_DTC84: provided-interface=DiagnosticMonitor
        provided-com-specs:
          operation=SetEventStatus, queue-length=1
          operation=SetEventStatusWithEnvdata, queue-length=1
          operation=ResetEventStatus, queue-length=1
          operation=PrestoreFreezeFrame, queue-length=1
          operation=ClearPrestoredFreezeFrame, queue-length=1
          operation=ResetEventDebounceStatus, queue-length=1
          operation=SetEventDisabled, queue-length=1
      Event_DemEventParameter_ECU3_DTC85: provided-interface=DiagnosticMonitor
        provided-com-specs:
          operation=SetEventStatus, queue-length=1
          operation=SetEventStatusWithEnvdata, queue-length=1
          operation=ResetEventStatus, queue-length=1
          operation=PrestoreFreezeFrame, queue-length=1
          operation=ClearPrestoredFreezeFrame, queue-length=1
          operation=ResetEventDebounceStatus, queue-length=1
          operation=SetEventDisabled, queue-length=1
      Event_DemEventParameter_ECU3_DTC86: provided-interface=DiagnosticMonitor
        provided-com-specs:
          operation=SetEventStatus, queue-length=1
          operation=SetEventStatusWithEnvdata, queue-length=1
          operation=ResetEventStatus, queue-length=1
          operation=PrestoreFreezeFrame, queue-length=1
          operation=ClearPrestoredFreezeFrame, queue-length=1
          operation=ResetEventDebounceStatus, queue-length=1
          operation=SetEventDisabled, queue-length=1
      Event_DemEventParameter_ECU3_DTC87: provided-interface=DiagnosticMonitor
        provided-com-specs:
          operation=SetEventStatus, queue-length=1
          operation=SetEventStatusWithEnvdata, queue-length=1
          operation=ResetEventStatus, queue-length=1
          operation=PrestoreFreezeFrame, queue-length=1
          operation=ClearPrestoredFreezeFrame, queue-length=1
          operation=ResetEventDebounceStatus, queue-length=1
          operation=SetEventDisabled, queue-length=1
      Event_DemEventParameter_ECU3_DTC88: provided-interface=DiagnosticMonitor
        provided-com-specs:
          operation=SetEventStatus, queue-length=1
          operation=SetEventStatusWithEnvdata, queue-length=1
          operation=ResetEventStatus, queue-length=1
          operation=PrestoreFreezeFrame, queue-length=1
          operation=ClearPrestoredFreezeFrame, queue-length=1
          operation=ResetEventDebounceStatus, queue-length=1
          operation=SetEventDisabled, queue-length=1
      Event_DemEventParameter_ECU3_DTC89: provided-interface=DiagnosticMonitor
        provided-com-specs:
          operation=SetEventStatus, queue-length=1
          operation=SetEventStatusWithEnvdata, queue-length=1
          operation=ResetEventStatus, queue-length=1
          operation=PrestoreFreezeFrame, queue-length=1
          operation=ClearPrestoredFreezeFrame, queue-length=1
          operation=ResetEventDebounceStatus, queue-length=1
          operation=SetEventDisabled, queue-length=1
      Event_DemEventParameter_ECU3_DTC90: provided-interface=DiagnosticMonitor
        provided-com-specs:
          operation=SetEventStatus, queue-length=1
          operation=SetEventStatusWithEnvdata, queue-length=1
          operation=ResetEventStatus, queue-length=1
          operation=PrestoreFreezeFrame, queue-length=1
          operation=ClearPrestoredFreezeFrame, queue-length=1
          operation=ResetEventDebounceStatus, queue-length=1
          operation=SetEventDisabled, queue-length=1
      Event_DemEventParameter_ECU3_DTC91: provided-interface=DiagnosticMonitor
        provided-com-specs:
          operation=SetEventStatus, queue-length=1
          operation=SetEventStatusWithEnvdata, queue-length=1
          operation=ResetEventStatus, queue-length=1
          operation=PrestoreFreezeFrame, queue-length=1
          operation=ClearPrestoredFreezeFrame, queue-length=1
          operation=ResetEventDebounceStatus, queue-length=1
          operation=SetEventDisabled, queue-length=1
      Event_DemEventParameter_ECU3_DTC92: provided-interface=DiagnosticMonitor
        provided-com-specs:
          operation=SetEventStatus, queue-length=1
          operation=SetEventStatusWithEnvdata, queue-length=1
          operation=ResetEventStatus, queue-length=1
          operation=PrestoreFreezeFrame, queue-length=1
          operation=ClearPrestoredFreezeFrame, queue-length=1
          operation=ResetEventDebounceStatus, queue-length=1
          operation=SetEventDisabled, queue-length=1
      Event_DemEventParameter_ECU3_DTC93: provided-interface=DiagnosticMonitor
        provided-com-specs:
          operation=SetEventStatus, queue-length=1
          operation=SetEventStatusWithEnvdata, queue-length=1
          operation=ResetEventStatus, queue-length=1
          operation=PrestoreFreezeFrame, queue-length=1
          operation=ClearPrestoredFreezeFrame, queue-length=1
          operation=ResetEventDebounceStatus, queue-length=1
          operation=SetEventDisabled, queue-length=1
      Event_DemEventParameter_ECU3_DTC94: provided-interface=DiagnosticMonitor
        provided-com-specs:
          operation=SetEventStatus, queue-length=1
          operation=SetEventStatusWithEnvdata, queue-length=1
          operation=ResetEventStatus, queue-length=1
          operation=PrestoreFreezeFrame, queue-length=1
          operation=ClearPrestoredFreezeFrame, queue-length=1
          operation=ResetEventDebounceStatus, queue-length=1
          operation=SetEventDisabled, queue-length=1
      Event_DemEventParameter_ECU3_DTC95: provided-interface=DiagnosticMonitor
        provided-com-specs:
          operation=SetEventStatus, queue-length=1
          operation=SetEventStatusWithEnvdata, queue-length=1
          operation=ResetEventStatus, queue-length=1
          operation=PrestoreFreezeFrame, queue-length=1
          operation=ClearPrestoredFreezeFrame, queue-length=1
          operation=ResetEventDebounceStatus, queue-length=1
          operation=SetEventDisabled, queue-length=1
      Event_DemEventParameter_ECU3_DTC96: provided-interface=DiagnosticMonitor
        provided-com-specs:
          operation=SetEventStatus, queue-length=1
          operation=SetEventStatusWithEnvdata, queue-length=1
          operation=ResetEventStatus, queue-length=1
          operation=PrestoreFreezeFrame, queue-length=1
          operation=ClearPrestoredFreezeFrame, queue-length=1
          operation=ResetEventDebounceStatus, queue-length=1
          operation=SetEventDisabled, queue-length=1
      Event_DemEventParameter_ECU3_DTC97: provided-interface=DiagnosticMonitor
        provided-com-specs:
          operation=SetEventStatus, queue-length=1
          operation=SetEventStatusWithEnvdata, queue-length=1
          operation=ResetEventStatus, queue-length=1
          operation=PrestoreFreezeFrame, queue-length=1
          operation=ClearPrestoredFreezeFrame, queue-length=1
          operation=ResetEventDebounceStatus, queue-length=1
          operation=SetEventDisabled, queue-length=1
      Event_DemEventParameter_ECU3_DTC98: provided-interface=DiagnosticMonitor
        provided-com-specs:
          operation=SetEventStatus, queue-length=1
          operation=SetEventStatusWithEnvdata, queue-length=1
          operation=ResetEventStatus, queue-length=1
          operation=PrestoreFreezeFrame, queue-length=1
          operation=ClearPrestoredFreezeFrame, queue-length=1
          operation=ResetEventDebounceStatus, queue-length=1
          operation=SetEventDisabled, queue-length=1
      Event_DemEventParameter_ECU3_DTC99: provided-interface=DiagnosticMonitor
        provided-com-specs:
          operation=SetEventStatus, queue-length=1
          operation=SetEventStatusWithEnvdata, queue-length=1
          operation=ResetEventStatus, queue-length=1
          operation=PrestoreFreezeFrame, queue-length=1
          operation=ClearPrestoredFreezeFrame, queue-length=1
          operation=ResetEventDebounceStatus, queue-length=1
          operation=SetEventDisabled, queue-length=1
      Event_DemEventParameter_ECU4_DTC00: provided-interface=DiagnosticMonitor
        provided-com-specs:
          operation=SetEventStatus, queue-length=1
          operation=SetEventStatusWithEnvdata, queue-length=1
          operation=ResetEventStatus, queue-length=1
          operation=PrestoreFreezeFrame, queue-length=1
          operation=ClearPrestoredFreezeFrame, queue-length=1
          operation=ResetEventDebounceStatus, queue-length=1
          operation=SetEventDisabled, queue-length=1
      Event_DemEventParameter_ECU4_DTC01: provided-interface=DiagnosticMonitor
        provided-com-specs:
          operation=SetEventStatus, queue-length=1
          operation=SetEventStatusWithEnvdata, queue-length=1
          operation=ResetEventStatus, queue-length=1
          operation=PrestoreFreezeFrame, queue-length=1
          operation=ClearPrestoredFreezeFrame, queue-length=1
          operation=ResetEventDebounceStatus, queue-length=1
          operation=SetEventDisabled, queue-length=1
      Event_DemEventParameter_ECU4_DTC02: provided-interface=DiagnosticMonitor
        provided-com-specs:
          operation=SetEventStatus, queue-length=1
          operation=SetEventStatusWithEnvdata, queue-length=1
          operation=ResetEventStatus, queue-length=1
          operation=PrestoreFreezeFrame, queue-length=1
          operation=ClearPrestoredFreezeFrame, queue-length=1
          operation=ResetEventDebounceStatus, queue-length=1
          operation=SetEventDisabled, queue-length=1
      Event_DemEventParameter_ECU4_DTC03: provided-interface=DiagnosticMonitor
        provided-com-specs:
          operation=SetEventStatus, queue-length=1
          operation=SetEventStatusWithEnvdata, queue-length=1
          operation=ResetEventStatus, queue-length=1
          operation=PrestoreFreezeFrame, queue-length=1
          operation=ClearPrestoredFreezeFrame, queue-length=1
          operation=ResetEventDebounceStatus, queue-length=1
          operation=SetEventDisabled, queue-length=1
      Event_DemEventParameter_ECU4_DTC04: provided-interface=DiagnosticMonitor
        provided-com-specs:
          operation=SetEventStatus, queue-length=1
          operation=SetEventStatusWithEnvdata, queue-length=1
          operation=ResetEventStatus, queue-length=1
          operation=PrestoreFreezeFrame, queue-length=1
          operation=ClearPrestoredFreezeFrame, queue-length=1
          operation=ResetEventDebounceStatus, queue-length=1
          operation=SetEventDisabled, queue-length=1
      Event_DemEventParameter_ECU4_DTC05: provided-interface=DiagnosticMonitor
        provided-com-specs:
          operation=SetEventStatus, queue-length=1
          operation=SetEventStatusWithEnvdata, queue-length=1
          operation=ResetEventStatus, queue-length=1
          operation=PrestoreFreezeFrame, queue-length=1
          operation=ClearPrestoredFreezeFrame, queue-length=1
          operation=ResetEventDebounceStatus, queue-length=1
          operation=SetEventDisabled, queue-length=1
      Event_DemEventParameter_ECU4_DTC06: provided-interface=DiagnosticMonitor
        provided-com-specs:
          operation=SetEventStatus, queue-length=1
          operation=SetEventStatusWithEnvdata, queue-length=1
          operation=ResetEventStatus, queue-length=1
          operation=PrestoreFreezeFrame, queue-length=1
          operation=ClearPrestoredFreezeFrame, queue-length=1
          operation=ResetEventDebounceStatus, queue-length=1
          operation=SetEventDisabled, queue-length=1
      Event_DemEventParameter_ECU4_DTC07: provided-interface=DiagnosticMonitor
        provided-com-specs:
          operation=SetEventStatus, queue-length=1
          operation=SetEventStatusWithEnvdata, queue-length=1
          operation=ResetEventStatus, queue-length=1
          operation=PrestoreFreezeFrame, queue-length=1
          operation=ClearPrestoredFreezeFrame, queue-length=1
          operation=ResetEventDebounceStatus, queue-length=1
          operation=SetEventDisabled, queue-length=1
      Event_DemEventParameter_ECU4_DTC08: provided-interface=DiagnosticMonitor
        provided-com-specs:
          operation=SetEventStatus, queue-length=1
          operation=SetEventStatusWithEnvdata, queue-length=1
          operation=ResetEventStatus, queue-length=1
          operation=PrestoreFreezeFrame, queue-length=1
          operation=ClearPrestoredFreezeFrame, queue-length=1
          operation=ResetEventDebounceStatus, queue-length=1
          operation=SetEventDisabled, queue-length=1
      Event_DemEventParameter_ECU4_DTC09: provided-interface=DiagnosticMonitor
        provided-com-specs:
          operation=SetEventStatus, queue-length=1
          operation=SetEventStatusWithEnvdata, queue-length=1
          operation=ResetEventStatus, queue-length=1
          operation=PrestoreFreezeFrame, queue-length=1
          operation=ClearPrestoredFreezeFrame, queue-length=1
          operation=ResetEventDebounceStatus, queue-length=1
          operation=SetEventDisabled, queue-length=1
      Event_DemEventParameter_ECU4_DTC10: provided-interface=DiagnosticMonitor
        provided-com-specs:
          operation=SetEventStatus, queue-length=1
          operation=SetEventStatusWithEnvdata, queue-length=1
          operation=ResetEventStatus, queue-length=1
          operation=PrestoreFreezeFrame, queue-length=1
          operation=ClearPrestoredFreezeFrame, queue-length=1
          operation=ResetEventDebounceStatus, queue-length=1
          operation=SetEventDisabled, queue-length=1
      Event_DemEventParameter_ECU4_DTC11: provided-interface=DiagnosticMonitor
        provided-com-specs:
          operation=SetEventStatus, queue-length=1
          operation=SetEventStatusWithEnvdata, queue-length=1
          operation=ResetEventStatus, queue-length=1
          operation=PrestoreFreezeFrame, queue-length=1
          operation=ClearPrestoredFreezeFrame, queue-length=1
          operation=ResetEventDebounceStatus, queue-length=1
          operation=SetEventDisabled, queue-length=1
      Event_DemEventParameter_ECU4_DTC12: provided-interface=DiagnosticMonitor
        provided-com-specs:
          operation=SetEventStatus, queue-length=1
          operation=SetEventStatusWithEnvdata, queue-length=1
          operation=ResetEventStatus, queue-length=1
          operation=PrestoreFreezeFrame, queue-length=1
          operation=ClearPrestoredFreezeFrame, queue-length=1
          operation=ResetEventDebounceStatus, queue-length=1
          operation=SetEventDisabled, queue-length=1
      Event_DemEventParameter_ECU4_DTC13: provided-interface=DiagnosticMonitor
        provided-com-specs:
          operation=SetEventStatus, queue-length=1
          operation=SetEventStatusWithEnvdata, queue-length=1
          operation=ResetEventStatus, queue-length=1
          operation=PrestoreFreezeFrame, queue-length=1
          operation=ClearPrestoredFreezeFrame, queue-length=1
          operation=ResetEventDebounceStatus, queue-length=1
          operation=SetEventDisabled, queue-length=1
      Event_DemEventParameter_ECU4_DTC14: provided-interface=DiagnosticMonitor
        provided-com-specs:
          operation=SetEventStatus, queue-length=1
          operation=SetEventStatusWithEnvdata, queue-length=1
          operation=ResetEventStatus, queue-length=1
          operation=PrestoreFreezeFrame, queue-length=1
          operation=ClearPrestoredFreezeFrame, queue-length=1
          operation=ResetEventDebounceStatus, queue-length=1
          operation=SetEventDisabled, queue-length=1
      Event_DemEventParameter_ECU4_DTC15: provided-interface=DiagnosticMonitor
        provided-com-specs:
          operation=SetEventStatus, queue-length=1
          operation=SetEventStatusWithEnvdata, queue-length=1
          operation=ResetEventStatus, queue-length=1
          operation=PrestoreFreezeFrame, queue-length=1
          operation=ClearPrestoredFreezeFrame, queue-length=1
          operation=ResetEventDebounceStatus, queue-length=1
          operation=SetEventDisabled, queue-length=1
      Event_DemEventParameter_ECU4_DTC16: provided-interface=DiagnosticMonitor
        provided-com-specs:
          operation=SetEventStatus, queue-length=1
          operation=SetEventStatusWithEnvdata, queue-length=1
          operation=ResetEventStatus, queue-length=1
          operation=PrestoreFreezeFrame, queue-length=1
          operation=ClearPrestoredFreezeFrame, queue-length=1
          operation=ResetEventDebounceStatus, queue-length=1
          operation=SetEventDisabled, queue-length=1
      Event_DemEventParameter_ECU4_DTC17: provided-interface=DiagnosticMonitor
        provided-com-specs:
          operation=SetEventStatus, queue-length=1
          operation=SetEventStatusWithEnvdata, queue-length=1
          operation=ResetEventStatus, queue-length=1
          operation=PrestoreFreezeFrame, queue-length=1
          operation=ClearPrestoredFreezeFrame, queue-length=1
          operation=ResetEventDebounceStatus, queue-length=1
          operation=SetEventDisabled, queue-length=1
      Event_DemEventParameter_ECU4_DTC18: provided-interface=DiagnosticMonitor
        provided-com-specs:
          operation=SetEventStatus, queue-length=1
          operation=SetEventStatusWithEnvdata, queue-length=1
          operation=ResetEventStatus, queue-length=1
          operation=PrestoreFreezeFrame, queue-length=1
          operation=ClearPrestoredFreezeFrame, queue-length=1
          operation=ResetEventDebounceStatus, queue-length=1
          operation=SetEventDisabled, queue-length=1
      Event_DemEventParameter_ECU4_DTC19: provided-interface=DiagnosticMonitor
        provided-com-specs:
          operation=SetEventStatus, queue-length=1
          operation=SetEventStatusWithEnvdata, queue-length=1
          operation=ResetEventStatus, queue-length=1
          operation=PrestoreFreezeFrame, queue-length=1
          operation=ClearPrestoredFreezeFrame, queue-length=1
          operation=ResetEventDebounceStatus, queue-length=1
          operation=SetEventDisabled, queue-length=1
      Event_DemEventParameter_ECU4_DTC20: provided-interface=DiagnosticMonitor
        provided-com-specs:
          operation=SetEventStatus, queue-length=1
          operation=SetEventStatusWithEnvdata, queue-length=1
          operation=ResetEventStatus, queue-length=1
          operation=PrestoreFreezeFrame, queue-length=1
          operation=ClearPrestoredFreezeFrame, queue-length=1
          operation=ResetEventDebounceStatus, queue-length=1
          operation=SetEventDisabled, queue-length=1
      Event_DemEventParameter_ECU4_DTC21: provided-interface=DiagnosticMonitor
        provided-com-specs:
          operation=SetEventStatus, queue-length=1
          operation=SetEventStatusWithEnvdata, queue-length=1
          operation=ResetEventStatus, queue-length=1
          operation=PrestoreFreezeFrame, queue-length=1
          operation=ClearPrestoredFreezeFrame, queue-length=1
          operation=ResetEventDebounceStatus, queue-length=1
          operation=SetEventDisabled, queue-length=1
      Event_DemEventParameter_ECU4_DTC22: provided-interface=DiagnosticMonitor
        provided-com-specs:
          operation=SetEventStatus, queue-length=1
          operation=SetEventStatusWithEnvdata, queue-length=1
          operation=ResetEventStatus, queue-length=1
          operation=PrestoreFreezeFrame, queue-length=1
          operation=ClearPrestoredFreezeFrame, queue-length=1
          operation=ResetEventDebounceStatus, queue-length=1
          operation=SetEventDisabled, queue-length=1
      Event_DemEventParameter_ECU4_DTC23: provided-interface=DiagnosticMonitor
        provided-com-specs:
          operation=SetEventStatus, queue-length=1
          operation=SetEventStatusWithEnvdata, queue-length=1
          operation=ResetEventStatus, queue-length=1
          operation=PrestoreFreezeFrame, queue-length=1
          operation=ClearPrestoredFreezeFrame, queue-length=1
          operation=ResetEventDebounceStatus, queue-length=1
          operation=SetEventDisabled, queue-length=1
      Event_DemEventParameter_ECU4_DTC24: provided-interface=DiagnosticMonitor
        provided-com-specs:
          operation=SetEventStatus, queue-length=1
          operation=SetEventStatusWithEnvdata, queue-length=1
          operation=ResetEventStatus, queue-length=1
          operation=PrestoreFreezeFrame, queue-length=1
          operation=ClearPrestoredFreezeFrame, queue-length=1
          operation=ResetEventDebounceStatus, queue-length=1
          operation=SetEventDisabled, queue-length=1
      Event_DemEventParameter_ECU4_DTC25: provided-interface=DiagnosticMonitor
        provided-com-specs:
          operation=SetEventStatus, queue-length=1
          operation=SetEventStatusWithEnvdata, queue-length=1
          operation=ResetEventStatus, queue-length=1
          operation=PrestoreFreezeFrame, queue-length=1
          operation=ClearPrestoredFreezeFrame, queue-length=1
          operation=ResetEventDebounceStatus, queue-length=1
          operation=SetEventDisabled, queue-length=1
      Event_DemEventParameter_ECU4_DTC26: provided-interface=DiagnosticMonitor
        provided-com-specs:
          operation=SetEventStatus, queue-length=1
          operation=SetEventStatusWithEnvdata, queue-length=1
          operation=ResetEventStatus, queue-length=1
          operation=PrestoreFreezeFrame, queue-length=1
          operation=ClearPrestoredFreezeFrame, queue-length=1
          operation=ResetEventDebounceStatus, queue-length=1
          operation=SetEventDisabled, queue-length=1
      Event_DemEventParameter_ECU4_DTC27: provided-interface=DiagnosticMonitor
        provided-com-specs:
          operation=SetEventStatus, queue-length=1
          operation=SetEventStatusWithEnvdata, queue-length=1
          operation=ResetEventStatus, queue-length=1
          operation=PrestoreFreezeFrame, queue-length=1
          operation=ClearPrestoredFreezeFrame, queue-length=1
          operation=ResetEventDebounceStatus, queue-length=1
          operation=SetEventDisabled, queue-length=1
      Event_DemEventParameter_ECU4_DTC28: provided-interface=DiagnosticMonitor
        provided-com-specs:
          operation=SetEventStatus, queue-length=1
          operation=SetEventStatusWithEnvdata, queue-length=1
          operation=ResetEventStatus, queue-length=1
          operation=PrestoreFreezeFrame, queue-length=1
          operation=ClearPrestoredFreezeFrame, queue-length=1
          operation=ResetEventDebounceStatus, queue-length=1
          operation=SetEventDisabled, queue-length=1
      Event_DemEventParameter_ECU4_DTC29: provided-interface=DiagnosticMonitor
        provided-com-specs:
          operation=SetEventStatus, queue-length=1
          operation=SetEventStatusWithEnvdata, queue-length=1
          operation=ResetEventStatus, queue-length=1
          operation=PrestoreFreezeFrame, queue-length=1
          operation=ClearPrestoredFreezeFrame, queue-length=1
          operation=ResetEventDebounceStatus, queue-length=1
          operation=SetEventDisabled, queue-length=1
      Event_DemEventParameter_ECU4_DTC30: provided-interface=DiagnosticMonitor
        provided-com-specs:
          operation=SetEventStatus, queue-length=1
          operation=SetEventStatusWithEnvdata, queue-length=1
          operation=ResetEventStatus, queue-length=1
          operation=PrestoreFreezeFrame, queue-length=1
          operation=ClearPrestoredFreezeFrame, queue-length=1
          operation=ResetEventDebounceStatus, queue-length=1
          operation=SetEventDisabled, queue-length=1
      Event_DemEventParameter_ECU4_DTC31: provided-interface=DiagnosticMonitor
        provided-com-specs:
          operation=SetEventStatus, queue-length=1
          operation=SetEventStatusWithEnvdata, queue-length=1
          operation=ResetEventStatus, queue-length=1
          operation=PrestoreFreezeFrame, queue-length=1
          operation=ClearPrestoredFreezeFrame, queue-length=1
          operation=ResetEventDebounceStatus, queue-length=1
          operation=SetEventDisabled, queue-length=1
      Event_DemEventParameter_ECU4_DTC32: provided-interface=DiagnosticMonitor
        provided-com-specs:
          operation=SetEventStatus, queue-length=1
          operation=SetEventStatusWithEnvdata, queue-length=1
          operation=ResetEventStatus, queue-length=1
          operation=PrestoreFreezeFrame, queue-length=1
          operation=ClearPrestoredFreezeFrame, queue-length=1
          operation=ResetEventDebounceStatus, queue-length=1
          operation=SetEventDisabled, queue-length=1
      Event_DemEventParameter_ECU4_DTC33: provided-interface=DiagnosticMonitor
        provided-com-specs:
          operation=SetEventStatus, queue-length=1
          operation=SetEventStatusWithEnvdata, queue-length=1
          operation=ResetEventStatus, queue-length=1
          operation=PrestoreFreezeFrame, queue-length=1
          operation=ClearPrestoredFreezeFrame, queue-length=1
          operation=ResetEventDebounceStatus, queue-length=1
          operation=SetEventDisabled, queue-length=1
      Event_DemEventParameter_ECU4_DTC34: provided-interface=DiagnosticMonitor
        provided-com-specs:
          operation=SetEventStatus, queue-length=1
          operation=SetEventStatusWithEnvdata, queue-length=1
          operation=ResetEventStatus, queue-length=1
          operation=PrestoreFreezeFrame, queue-length=1
          operation=ClearPrestoredFreezeFrame, queue-length=1
          operation=ResetEventDebounceStatus, queue-length=1
          operation=SetEventDisabled, queue-length=1
      Event_DemEventParameter_ECU4_DTC35: provided-interface=DiagnosticMonitor
        provided-com-specs:
          operation=SetEventStatus, queue-length=1
          operation=SetEventStatusWithEnvdata, queue-length=1
          operation=ResetEventStatus, queue-length=1
          operation=PrestoreFreezeFrame, queue-length=1
          operation=ClearPrestoredFreezeFrame, queue-length=1
          operation=ResetEventDebounceStatus, queue-length=1
          operation=SetEventDisabled, queue-length=1
      Event_DemEventParameter_ECU4_DTC36: provided-interface=DiagnosticMonitor
        provided-com-specs:
          operation=SetEventStatus, queue-length=1
          operation=SetEventStatusWithEnvdata, queue-length=1
          operation=ResetEventStatus, queue-length=1
          operation=PrestoreFreezeFrame, queue-length=1
          operation=ClearPrestoredFreezeFrame, queue-length=1
          operation=ResetEventDebounceStatus, queue-length=1
          operation=SetEventDisabled, queue-length=1
      Event_DemEventParameter_ECU4_DTC37: provided-interface=DiagnosticMonitor
        provided-com-specs:
          operation=SetEventStatus, queue-length=1
          operation=SetEventStatusWithEnvdata, queue-length=1
          operation=ResetEventStatus, queue-length=1
          operation=PrestoreFreezeFrame, queue-length=1
          operation=ClearPrestoredFreezeFrame, queue-length=1
          operation=ResetEventDebounceStatus, queue-length=1
          operation=SetEventDisabled, queue-length=1
      Event_DemEventParameter_ECU4_DTC38: provided-interface=DiagnosticMonitor
        provided-com-specs:
          operation=SetEventStatus, queue-length=1
          operation=SetEventStatusWithEnvdata, queue-length=1
          operation=ResetEventStatus, queue-length=1
          operation=PrestoreFreezeFrame, queue-length=1
          operation=ClearPrestoredFreezeFrame, queue-length=1
          operation=ResetEventDebounceStatus, queue-length=1
          operation=SetEventDisabled, queue-length=1
      Event_DemEventParameter_ECU4_DTC39: provided-interface=DiagnosticMonitor
        provided-com-specs:
          operation=SetEventStatus, queue-length=1
          operation=SetEventStatusWithEnvdata, queue-length=1
          operation=ResetEventStatus, queue-length=1
          operation=PrestoreFreezeFrame, queue-length=1
          operation=ClearPrestoredFreezeFrame, queue-length=1
          operation=ResetEventDebounceStatus, queue-length=1
          operation=SetEventDisabled, queue-length=1
      Event_DemEventParameter_ECU4_DTC40: provided-interface=DiagnosticMonitor
        provided-com-specs:
          operation=SetEventStatus, queue-length=1
          operation=SetEventStatusWithEnvdata, queue-length=1
          operation=ResetEventStatus, queue-length=1
          operation=PrestoreFreezeFrame, queue-length=1
          operation=ClearPrestoredFreezeFrame, queue-length=1
          operation=ResetEventDebounceStatus, queue-length=1
          operation=SetEventDisabled, queue-length=1
      Event_DemEventParameter_ECU4_DTC41: provided-interface=DiagnosticMonitor
        provided-com-specs:
          operation=SetEventStatus, queue-length=1
          operation=SetEventStatusWithEnvdata, queue-length=1
          operation=ResetEventStatus, queue-length=1
          operation=PrestoreFreezeFrame, queue-length=1
          operation=ClearPrestoredFreezeFrame, queue-length=1
          operation=ResetEventDebounceStatus, queue-length=1
          operation=SetEventDisabled, queue-length=1
      Event_DemEventParameter_ECU4_DTC42: provided-interface=DiagnosticMonitor
        provided-com-specs:
          operation=SetEventStatus, queue-length=1
          operation=SetEventStatusWithEnvdata, queue-length=1
          operation=ResetEventStatus, queue-length=1
          operation=PrestoreFreezeFrame, queue-length=1
          operation=ClearPrestoredFreezeFrame, queue-length=1
          operation=ResetEventDebounceStatus, queue-length=1
          operation=SetEventDisabled, queue-length=1
      Event_DemEventParameter_ECU4_DTC43: provided-interface=DiagnosticMonitor
        provided-com-specs:
          operation=SetEventStatus, queue-length=1
          operation=SetEventStatusWithEnvdata, queue-length=1
          operation=ResetEventStatus, queue-length=1
          operation=PrestoreFreezeFrame, queue-length=1
          operation=ClearPrestoredFreezeFrame, queue-length=1
          operation=ResetEventDebounceStatus, queue-length=1
          operation=SetEventDisabled, queue-length=1
      Event_DemEventParameter_ECU4_DTC44: provided-interface=DiagnosticMonitor
        provided-com-specs:
          operation=SetEventStatus, queue-length=1
          operation=SetEventStatusWithEnvdata, queue-length=1
          operation=ResetEventStatus, queue-length=1
          operation=PrestoreFreezeFrame, queue-length=1
          operation=ClearPrestoredFreezeFrame, queue-length=1
          operation=ResetEventDebounceStatus, queue-length=1
          operation=SetEventDisabled, queue-length=1
      Event_DemEventParameter_ECU4_DTC45: provided-interface=DiagnosticMonitor
        provided-com-specs:
          operation=SetEventStatus, queue-length=1
          operation=SetEventStatusWithEnvdata, queue-length=1
          operation=ResetEventStatus, queue-length=1
          operation=PrestoreFreezeFrame, queue-length=1
          operation=ClearPrestoredFreezeFrame, queue-length=1
          operation=ResetEventDebounceStatus, queue-length=1
          operation=SetEventDisabled, queue-length=1
      Event_DemEventParameter_ECU4_DTC46: provided-interface=DiagnosticMonitor
        provided-com-specs:
          operation=SetEventStatus, queue-length=1
          operation=SetEventStatusWithEnvdata, queue-length=1
          operation=ResetEventStatus, queue-length=1
          operation=PrestoreFreezeFrame, queue-length=1
          operation=ClearPrestoredFreezeFrame, queue-length=1
          operation=ResetEventDebounceStatus, queue-length=1
          operation=SetEventDisabled, queue-length=1
      Event_DemEventParameter_ECU4_DTC47: provided-interface=DiagnosticMonitor
        provided-com-specs:
          operation=SetEventStatus, queue-length=1
          operation=SetEventStatusWithEnvdata, queue-length=1
          operation=ResetEventStatus, queue-length=1
          operation=PrestoreFreezeFrame, queue-length=1
          operation=ClearPrestoredFreezeFrame, queue-length=1
          operation=ResetEventDebounceStatus, queue-length=1
          operation=SetEventDisabled, queue-length=1
      Event_DemEventParameter_ECU4_DTC48: provided-interface=DiagnosticMonitor
        provided-com-specs:
          operation=SetEventStatus, queue-length=1
          operation=SetEventStatusWithEnvdata, queue-length=1
          operation=ResetEventStatus, queue-length=1
          operation=PrestoreFreezeFrame, queue-length=1
          operation=ClearPrestoredFreezeFrame, queue-length=1
          operation=ResetEventDebounceStatus, queue-length=1
          operation=SetEventDisabled, queue-length=1
      Event_DemEventParameter_ECU4_DTC49: provided-interface=DiagnosticMonitor
        provided-com-specs:
          operation=SetEventStatus, queue-length=1
          operation=SetEventStatusWithEnvdata, queue-length=1
          operation=ResetEventStatus, queue-length=1
          operation=PrestoreFreezeFrame, queue-length=1
          operation=ClearPrestoredFreezeFrame, queue-length=1
          operation=ResetEventDebounceStatus, queue-length=1
          operation=SetEventDisabled, queue-length=1
      Event_DemEventParameter_ECU4_DTC50: provided-interface=DiagnosticMonitor
        provided-com-specs:
          operation=SetEventStatus, queue-length=1
          operation=SetEventStatusWithEnvdata, queue-length=1
          operation=ResetEventStatus, queue-length=1
          operation=PrestoreFreezeFrame, queue-length=1
          operation=ClearPrestoredFreezeFrame, queue-length=1
          operation=ResetEventDebounceStatus, queue-length=1
          operation=SetEventDisabled, queue-length=1
      Event_DemEventParameter_ECU4_DTC51: provided-interface=DiagnosticMonitor
        provided-com-specs:
          operation=SetEventStatus, queue-length=1
          operation=SetEventStatusWithEnvdata, queue-length=1
          operation=ResetEventStatus, queue-length=1
          operation=PrestoreFreezeFrame, queue-length=1
          operation=ClearPrestoredFreezeFrame, queue-length=1
          operation=ResetEventDebounceStatus, queue-length=1
          operation=SetEventDisabled, queue-length=1
      Event_DemEventParameter_ECU4_DTC52: provided-interface=DiagnosticMonitor
        provided-com-specs:
          operation=SetEventStatus, queue-length=1
          operation=SetEventStatusWithEnvdata, queue-length=1
          operation=ResetEventStatus, queue-length=1
          operation=PrestoreFreezeFrame, queue-length=1
          operation=ClearPrestoredFreezeFrame, queue-length=1
          operation=ResetEventDebounceStatus, queue-length=1
          operation=SetEventDisabled, queue-length=1
      Event_DemEventParameter_ECU4_DTC53: provided-interface=DiagnosticMonitor
        provided-com-specs:
          operation=SetEventStatus, queue-length=1
          operation=SetEventStatusWithEnvdata, queue-length=1
          operation=ResetEventStatus, queue-length=1
          operation=PrestoreFreezeFrame, queue-length=1
          operation=ClearPrestoredFreezeFrame, queue-length=1
          operation=ResetEventDebounceStatus, queue-length=1
          operation=SetEventDisabled, queue-length=1
      Event_DemEventParameter_ECU4_DTC54: provided-interface=DiagnosticMonitor
        provided-com-specs:
          operation=SetEventStatus, queue-length=1
          operation=SetEventStatusWithEnvdata, queue-length=1
          operation=ResetEventStatus, queue-length=1
          operation=PrestoreFreezeFrame, queue-length=1
          operation=ClearPrestoredFreezeFrame, queue-length=1
          operation=ResetEventDebounceStatus, queue-length=1
          operation=SetEventDisabled, queue-length=1
      Event_DemEventParameter_ECU4_DTC55: provided-interface=DiagnosticMonitor
        provided-com-specs:
          operation=SetEventStatus, queue-length=1
          operation=SetEventStatusWithEnvdata, queue-length=1
          operation=ResetEventStatus, queue-length=1
          operation=PrestoreFreezeFrame, queue-length=1
          operation=ClearPrestoredFreezeFrame, queue-length=1
          operation=ResetEventDebounceStatus, queue-length=1
          operation=SetEventDisabled, queue-length=1
      Event_DemEventParameter_ECU4_DTC56: provided-interface=DiagnosticMonitor
        provided-com-specs:
          operation=SetEventStatus, queue-length=1
          operation=SetEventStatusWithEnvdata, queue-length=1
          operation=ResetEventStatus, queue-length=1
          operation=PrestoreFreezeFrame, queue-length=1
          operation=ClearPrestoredFreezeFrame, queue-length=1
          operation=ResetEventDebounceStatus, queue-length=1
          operation=SetEventDisabled, queue-length=1
      Event_DemEventParameter_ECU4_DTC57: provided-interface=DiagnosticMonitor
        provided-com-specs:
          operation=SetEventStatus, queue-length=1
          operation=SetEventStatusWithEnvdata, queue-length=1
          operation=ResetEventStatus, queue-length=1
          operation=PrestoreFreezeFrame, queue-length=1
          operation=ClearPrestoredFreezeFrame, queue-length=1
          operation=ResetEventDebounceStatus, queue-length=1
          operation=SetEventDisabled, queue-length=1
      Event_DemEventParameter_ECU4_DTC58: provided-interface=DiagnosticMonitor
        provided-com-specs:
          operation=SetEventStatus, queue-length=1
          operation=SetEventStatusWithEnvdata, queue-length=1
          operation=ResetEventStatus, queue-length=1
          operation=PrestoreFreezeFrame, queue-length=1
          operation=ClearPrestoredFreezeFrame, queue-length=1
          operation=ResetEventDebounceStatus, queue-length=1
          operation=SetEventDisabled, queue-length=1
      Event_DemEventParameter_ECU4_DTC59: provided-interface=DiagnosticMonitor
        provided-com-specs:
          operation=SetEventStatus, queue-length=1
          operation=SetEventStatusWithEnvdata, queue-length=1
          operation=ResetEventStatus, queue-length=1
          operation=PrestoreFreezeFrame, queue-length=1
          operation=ClearPrestoredFreezeFrame, queue-length=1
          operation=ResetEventDebounceStatus, queue-length=1
          operation=SetEventDisabled, queue-length=1
      Event_DemEventParameter_ECU4_DTC60: provided-interface=DiagnosticMonitor
        provided-com-specs:
          operation=SetEventStatus, queue-length=1
          operation=SetEventStatusWithEnvdata, queue-length=1
          operation=ResetEventStatus, queue-length=1
          operation=PrestoreFreezeFrame, queue-length=1
          operation=ClearPrestoredFreezeFrame, queue-length=1
          operation=ResetEventDebounceStatus, queue-length=1
          operation=SetEventDisabled, queue-length=1
      Event_DemEventParameter_ECU4_DTC61: provided-interface=DiagnosticMonitor
        provided-com-specs:
          operation=SetEventStatus, queue-length=1
          operation=SetEventStatusWithEnvdata, queue-length=1
          operation=ResetEventStatus, queue-length=1
          operation=PrestoreFreezeFrame, queue-length=1
          operation=ClearPrestoredFreezeFrame, queue-length=1
          operation=ResetEventDebounceStatus, queue-length=1
          operation=SetEventDisabled, queue-length=1
      Event_DemEventParameter_ECU4_DTC62: provided-interface=DiagnosticMonitor
        provided-com-specs:
          operation=SetEventStatus, queue-length=1
          operation=SetEventStatusWithEnvdata, queue-length=1
          operation=ResetEventStatus, queue-length=1
          operation=PrestoreFreezeFrame, queue-length=1
          operation=ClearPrestoredFreezeFrame, queue-length=1
          operation=ResetEventDebounceStatus, queue-length=1
          operation=SetEventDisabled, queue-length=1
      Event_DemEventParameter_ECU4_DTC63: provided-interface=DiagnosticMonitor
        provided-com-specs:
          operation=SetEventStatus, queue-length=1
          operation=SetEventStatusWithEnvdata, queue-length=1
          operation=ResetEventStatus, queue-length=1
          operation=PrestoreFreezeFrame, queue-length=1
          operation=ClearPrestoredFreezeFrame, queue-length=1
          operation=ResetEventDebounceStatus, queue-length=1
          operation=SetEventDisabled, queue-length=1
      Event_DemEventParameter_ECU4_DTC64: provided-interface=DiagnosticMonitor
        provided-com-specs:
          operation=SetEventStatus, queue-length=1
          operation=SetEventStatusWithEnvdata, queue-length=1
          operation=ResetEventStatus, queue-length=1
          operation=PrestoreFreezeFrame, queue-length=1
          operation=ClearPrestoredFreezeFrame, queue-length=1
          operation=ResetEventDebounceStatus, queue-length=1
          operation=SetEventDisabled, queue-length=1
      Event_DemEventParameter_ECU4_DTC65: provided-interface=DiagnosticMonitor
        provided-com-specs:
          operation=SetEventStatus, queue-length=1
          operation=SetEventStatusWithEnvdata, queue-length=1
          operation=ResetEventStatus, queue-length=1
          operation=PrestoreFreezeFrame, queue-length=1
          operation=ClearPrestoredFreezeFrame, queue-length=1
          operation=ResetEventDebounceStatus, queue-length=1
          operation=SetEventDisabled, queue-length=1
      Event_DemEventParameter_ECU4_DTC66: provided-interface=DiagnosticMonitor
        provided-com-specs:
          operation=SetEventStatus, queue-length=1
          operation=SetEventStatusWithEnvdata, queue-length=1
          operation=ResetEventStatus, queue-length=1
          operation=PrestoreFreezeFrame, queue-length=1
          operation=ClearPrestoredFreezeFrame, queue-length=1
          operation=ResetEventDebounceStatus, queue-length=1
          operation=SetEventDisabled, queue-length=1
      Event_DemEventParameter_ECU4_DTC67: provided-interface=DiagnosticMonitor
        provided-com-specs:
          operation=SetEventStatus, queue-length=1
          operation=SetEventStatusWithEnvdata, queue-length=1
          operation=ResetEventStatus, queue-length=1
          operation=PrestoreFreezeFrame, queue-length=1
          operation=ClearPrestoredFreezeFrame, queue-length=1
          operation=ResetEventDebounceStatus, queue-length=1
          operation=SetEventDisabled, queue-length=1
      Event_DemEventParameter_ECU4_DTC68: provided-interface=DiagnosticMonitor
        provided-com-specs:
          operation=SetEventStatus, queue-length=1
          operation=SetEventStatusWithEnvdata, queue-length=1
          operation=ResetEventStatus, queue-length=1
          operation=PrestoreFreezeFrame, queue-length=1
          operation=ClearPrestoredFreezeFrame, queue-length=1
          operation=ResetEventDebounceStatus, queue-length=1
          operation=SetEventDisabled, queue-length=1
      Event_DemEventParameter_ECU4_DTC69: provided-interface=DiagnosticMonitor
        provided-com-specs:
          operation=SetEventStatus, queue-length=1
          operation=SetEventStatusWithEnvdata, queue-length=1
          operation=ResetEventStatus, queue-length=1
          operation=PrestoreFreezeFrame, queue-length=1
          operation=ClearPrestoredFreezeFrame, queue-length=1
          operation=ResetEventDebounceStatus, queue-length=1
          operation=SetEventDisabled, queue-length=1
      Event_DemEventParameter_ECU4_DTC70: provided-interface=DiagnosticMonitor
        provided-com-specs:
          operation=SetEventStatus, queue-length=1
          operation=SetEventStatusWithEnvdata, queue-length=1
          operation=ResetEventStatus, queue-length=1
          operation=PrestoreFreezeFrame, queue-length=1
          operation=ClearPrestoredFreezeFrame, queue-length=1
          operation=ResetEventDebounceStatus, queue-length=1
          operation=SetEventDisabled, queue-length=1
      Event_DemEventParameter_ECU4_DTC71: provided-interface=DiagnosticMonitor
        provided-com-specs:
          operation=SetEventStatus, queue-length=1
          operation=SetEventStatusWithEnvdata, queue-length=1
          operation=ResetEventStatus, queue-length=1
          operation=PrestoreFreezeFrame, queue-length=1
          operation=ClearPrestoredFreezeFrame, queue-length=1
          operation=ResetEventDebounceStatus, queue-length=1
          operation=SetEventDisabled, queue-length=1
      Event_DemEventParameter_ECU4_DTC72: provided-interface=DiagnosticMonitor
        provided-com-specs:
          operation=SetEventStatus, queue-length=1
          operation=SetEventStatusWithEnvdata, queue-length=1
          operation=ResetEventStatus, queue-length=1
          operation=PrestoreFreezeFrame, queue-length=1
          operation=ClearPrestoredFreezeFrame, queue-length=1
          operation=ResetEventDebounceStatus, queue-length=1
          operation=SetEventDisabled, queue-length=1
      Event_DemEventParameter_ECU4_DTC73: provided-interface=DiagnosticMonitor
        provided-com-specs:
          operation=SetEventStatus, queue-length=1
          operation=SetEventStatusWithEnvdata, queue-length=1
          operation=ResetEventStatus, queue-length=1
          operation=PrestoreFreezeFrame, queue-length=1
          operation=ClearPrestoredFreezeFrame, queue-length=1
          operation=ResetEventDebounceStatus, queue-length=1
          operation=SetEventDisabled, queue-length=1
      Event_DemEventParameter_ECU4_DTC74: provided-interface=DiagnosticMonitor
        provided-com-specs:
          operation=SetEventStatus, queue-length=1
          operation=SetEventStatusWithEnvdata, queue-length=1
          operation=ResetEventStatus, queue-length=1
          operation=PrestoreFreezeFrame, queue-length=1
          operation=ClearPrestoredFreezeFrame, queue-length=1
          operation=ResetEventDebounceStatus, queue-length=1
          operation=SetEventDisabled, queue-length=1
      Event_DemEventParameter_ECU4_DTC75: provided-interface=DiagnosticMonitor
        provided-com-specs:
          operation=SetEventStatus, queue-length=1
          operation=SetEventStatusWithEnvdata, queue-length=1
          operation=ResetEventStatus, queue-length=1
          operation=PrestoreFreezeFrame, queue-length=1
          operation=ClearPrestoredFreezeFrame, queue-length=1
          operation=ResetEventDebounceStatus, queue-length=1
          operation=SetEventDisabled, queue-length=1
      Event_DemEventParameter_ECU4_DTC76: provided-interface=DiagnosticMonitor
        provided-com-specs:
          operation=SetEventStatus, queue-length=1
          operation=SetEventStatusWithEnvdata, queue-length=1
          operation=ResetEventStatus, queue-length=1
          operation=PrestoreFreezeFrame, queue-length=1
          operation=ClearPrestoredFreezeFrame, queue-length=1
          operation=ResetEventDebounceStatus, queue-length=1
          operation=SetEventDisabled, queue-length=1
      Event_DemEventParameter_ECU4_DTC77: provided-interface=DiagnosticMonitor
        provided-com-specs:
          operation=SetEventStatus, queue-length=1
          operation=SetEventStatusWithEnvdata, queue-length=1
          operation=ResetEventStatus, queue-length=1
          operation=PrestoreFreezeFrame, queue-length=1
          operation=ClearPrestoredFreezeFrame, queue-length=1
          operation=ResetEventDebounceStatus, queue-length=1
          operation=SetEventDisabled, queue-length=1
      Event_DemEventParameter_ECU4_DTC78: provided-interface=DiagnosticMonitor
        provided-com-specs:
          operation=SetEventStatus, queue-length=1
          operation=SetEventStatusWithEnvdata, queue-length=1
          operation=ResetEventStatus, queue-length=1
          operation=PrestoreFreezeFrame, queue-length=1
          operation=ClearPrestoredFreezeFrame, queue-length=1
          operation=ResetEventDebounceStatus, queue-length=1
          operation=SetEventDisabled, queue-length=1
      Event_DemEventParameter_ECU4_DTC79: provided-interface=DiagnosticMonitor
        provided-com-specs:
          operation=SetEventStatus, queue-length=1
          operation=SetEventStatusWithEnvdata, queue-length=1
          operation=ResetEventStatus, queue-length=1
          operation=PrestoreFreezeFrame, queue-length=1
          operation=ClearPrestoredFreezeFrame, queue-length=1
          operation=ResetEventDebounceStatus, queue-length=1
          operation=SetEventDisabled, queue-length=1
      Event_DemEventParameter_ECU4_DTC80: provided-interface=DiagnosticMonitor
        provided-com-specs:
          operation=SetEventStatus, queue-length=1
          operation=SetEventStatusWithEnvdata, queue-length=1
          operation=ResetEventStatus, queue-length=1
          operation=PrestoreFreezeFrame, queue-length=1
          operation=ClearPrestoredFreezeFrame, queue-length=1
          operation=ResetEventDebounceStatus, queue-length=1
          operation=SetEventDisabled, queue-length=1
      Event_DemEventParameter_ECU4_DTC81: provided-interface=DiagnosticMonitor
        provided-com-specs:
          operation=SetEventStatus, queue-length=1
          operation=SetEventStatusWithEnvdata, queue-length=1
          operation=ResetEventStatus, queue-length=1
          operation=PrestoreFreezeFrame, queue-length=1
          operation=ClearPrestoredFreezeFrame, queue-length=1
          operation=ResetEventDebounceStatus, queue-length=1
          operation=SetEventDisabled, queue-length=1
      Event_DemEventParameter_ECU4_DTC82: provided-interface=DiagnosticMonitor
        provided-com-specs:
          operation=SetEventStatus, queue-length=1
          operation=SetEventStatusWithEnvdata, queue-length=1
          operation=ResetEventStatus, queue-length=1
          operation=PrestoreFreezeFrame, queue-length=1
          operation=ClearPrestoredFreezeFrame, queue-length=1
          operation=ResetEventDebounceStatus, queue-length=1
          operation=SetEventDisabled, queue-length=1
      Event_DemEventParameter_ECU4_DTC83: provided-interface=DiagnosticMonitor
        provided-com-specs:
          operation=SetEventStatus, queue-length=1
          operation=SetEventStatusWithEnvdata, queue-length=1
          operation=ResetEventStatus, queue-length=1
          operation=PrestoreFreezeFrame, queue-length=1
          operation=ClearPrestoredFreezeFrame, queue-length=1
          operation=ResetEventDebounceStatus, queue-length=1
          operation=SetEventDisabled, queue-length=1
      Event_DemEventParameter_ECU4_DTC84: provided-interface=DiagnosticMonitor
        provided-com-specs:
          operation=SetEventStatus, queue-length=1
          operation=SetEventStatusWithEnvdata, queue-length=1
          operation=ResetEventStatus, queue-length=1
          operation=PrestoreFreezeFrame, queue-length=1
          operation=ClearPrestoredFreezeFrame, queue-length=1
          operation=ResetEventDebounceStatus, queue-length=1
          operation=SetEventDisabled, queue-length=1
      Event_DemEventParameter_ECU4_DTC85: provided-interface=DiagnosticMonitor
        provided-com-specs:
          operation=SetEventStatus, queue-length=1
          operation=SetEventStatusWithEnvdata, queue-length=1
          operation=ResetEventStatus, queue-length=1
          operation=PrestoreFreezeFrame, queue-length=1
          operation=ClearPrestoredFreezeFrame, queue-length=1
          operation=ResetEventDebounceStatus, queue-length=1
          operation=SetEventDisabled, queue-length=1
      Event_DemEventParameter_ECU4_DTC86: provided-interface=DiagnosticMonitor
        provided-com-specs:
          operation=SetEventStatus, queue-length=1
          operation=SetEventStatusWithEnvdata, queue-length=1
          operation=ResetEventStatus, queue-length=1
          operation=PrestoreFreezeFrame, queue-length=1
          operation=ClearPrestoredFreezeFrame, queue-length=1
          operation=ResetEventDebounceStatus, queue-length=1
          operation=SetEventDisabled, queue-length=1
      Event_DemEventParameter_ECU4_DTC87: provided-interface=DiagnosticMonitor
        provided-com-specs:
          operation=SetEventStatus, queue-length=1
          operation=SetEventStatusWithEnvdata, queue-length=1
          operation=ResetEventStatus, queue-length=1
          operation=PrestoreFreezeFrame, queue-length=1
          operation=ClearPrestoredFreezeFrame, queue-length=1
          operation=ResetEventDebounceStatus, queue-length=1
          operation=SetEventDisabled, queue-length=1
      Event_DemEventParameter_ECU4_DTC88: provided-interface=DiagnosticMonitor
        provided-com-specs:
          operation=SetEventStatus, queue-length=1
          operation=SetEventStatusWithEnvdata, queue-length=1
          operation=ResetEventStatus, queue-length=1
          operation=PrestoreFreezeFrame, queue-length=1
          operation=ClearPrestoredFreezeFrame, queue-length=1
          operation=ResetEventDebounceStatus, queue-length=1
          operation=SetEventDisabled, queue-length=1
      Event_DemEventParameter_ECU4_DTC89: provided-interface=DiagnosticMonitor
        provided-com-specs:
          operation=SetEventStatus, queue-length=1
          operation=SetEventStatusWithEnvdata, queue-length=1
          operation=ResetEventStatus, queue-length=1
          operation=PrestoreFreezeFrame, queue-length=1
          operation=ClearPrestoredFreezeFrame, queue-length=1
          operation=ResetEventDebounceStatus, queue-length=1
          operation=SetEventDisabled, queue-length=1
